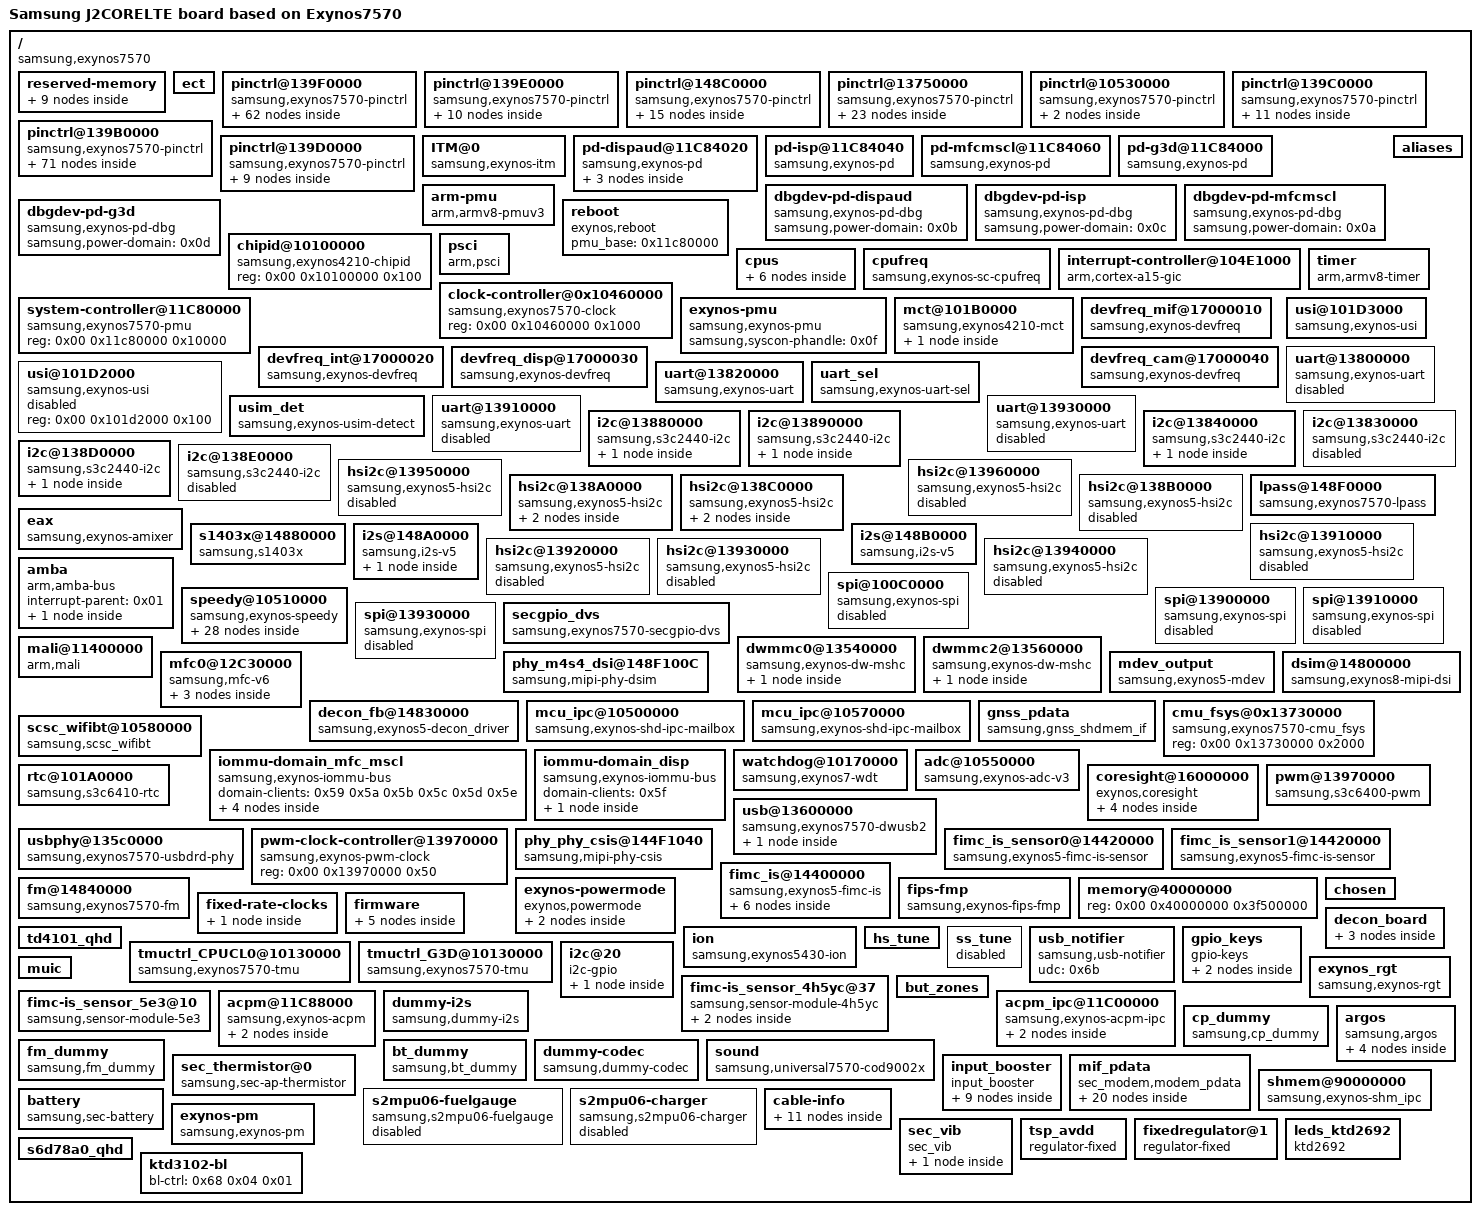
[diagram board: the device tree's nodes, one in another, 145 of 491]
/dts-v1/;

/memreserve/	0x000000007e700000 0x0000000000100000;
/ {
	compatible = "samsung,exynos7570", "samsung,exynos4210";
	interrupt-parent = <0x01>;
	#address-cells = <0x02>;
	#size-cells = <0x01>;
	model = "Samsung J2CORELTE board based on Exynos7570";
	model_info-chip = <0x1d92>;
	model_info-platform = "android";
	model_info-subtype = "samsung";
	model_info-hw_rev = <0x00>;
	model_info-hw_rev_end = <0x00>;

	reserved-memory {
		#address-cells = <0x02>;
		#size-cells = <0x01>;
		ranges;

		camera {
			compatible = "exynos8890-ion,camera";
			reg = <0x00 0x710ef000 0x1000>;
			id = <0x0a>;
		};

		video_nfw {
			compatible = "exynos7570-mfc,vnfw";
			reg = <0x00 0x710f0000 0x110000>;
			fixed_upper_base = <0xffffff80>;
			fixed_lower_base = <0x40000000>;
		};

		video_stream {
			compatible = "exynos8890-ion,vstream";
			secure;
			reg = <0x00 0x72200000 0x100000>;
			id = <0x03>;
			compat-id = <0x19 0x1f>;
		};

		modem_if {
			compatible = "exynos,modem_if";
			reg = <0x00 0x73400000 0x4c00000>;
		};

		wifibt_if {
			compatible = "exynos,wifibt_if";
			reg = <0x00 0x79000000 0x400000>;
		};

		crypto {
			compatible = "exynos8890-ion,crypto";
			reusable;
			reg = <0x00 0x79400000 0x800000>;
			id = <0x01>;
		};

		video_frame {
			compatible = "exynos8890-ion,vframe";
			secure;
			reusable;
			ion,bulk_reclaim;
			reg = <0x00 0x79c00000 0x3800000>;
			id = <0x05>;
			compat-id = <0x1a 0x1d>;
		};

		video_scaler {
			compatible = "exynos8890-ion,vscaler";
			secure;
			reusable;
			reg = <0x00 0x71200000 0x1000000>;
			id = <0x06>;
			compat-id = <0x1c>;
		};

		gnss_if {
			compatible = "exynos,gnss_if";
			reg = <0x00 0x7e100000 0x200000>;
		};
	};

	ect {
		parameter_address = <0x7e0fa000>;
		parameter_size = <0x6000>;
	};

	pinctrl@139F0000 {
		compatible = "samsung,exynos7570-pinctrl";
		reg = <0x00 0x139f0000 0x1000>;
		interrupts = <0x00 0x00 0x00 0x00 0x01 0x00 0x00 0x02 0x00 0x00 0x03 0x00 0x00 0x04 0x00 0x00 0x05 0x00 0x00 0x06 0x00 0x00 0x07 0x00 0x00 0x08 0x00 0x00 0x09 0x00 0x00 0x0a 0x00 0x00 0x0b 0x00 0x00 0x0c 0x00 0x00 0x0d 0x00 0x00 0x0e 0x00 0x00 0x0f 0x00>;
		pinctrl-names = "default";
		pinctrl-0 = <0x02>;

		etc0 {
			gpio-controller;
			#gpio-cells = <0x02>;
			interrupt-controller;
			#interrupt-cells = <0x02>;
		};

		etc1 {
			gpio-controller;
			#gpio-cells = <0x02>;
			interrupt-controller;
			#interrupt-cells = <0x02>;
		};

		gpa0 {
			gpio-controller;
			#gpio-cells = <0x02>;
			interrupt-controller;
			#interrupt-cells = <0x02>;
			interrupt-parent = <0x01>;
			interrupts = <0x00 0x00 0x00 0x00 0x01 0x00 0x00 0x02 0x00 0x00 0x03 0x00 0x00 0x04 0x00 0x00 0x05 0x00 0x00 0x06 0x00 0x00 0x07 0x00>;
			linux,phandle = <0x3a>;
			phandle = <0x3a>;
		};

		dwmmc2_cd_ext_irq {
			samsung,pins = "gpa0-1";
			samsung,pin-function = <0x0f>;
			samsung,pin-pud = <0x00>;
			samsung,pin-drv = <0x04>;
			linux,phandle = <0x4e>;
			phandle = <0x4e>;
		};

		gpa1 {
			gpio-controller;
			#gpio-cells = <0x02>;
			interrupt-controller;
			#interrupt-cells = <0x03>;
			interrupt-parent = <0x01>;
			interrupts = <0x00 0x08 0x00 0x00 0x09 0x00 0x00 0x0a 0x00 0x00 0x0b 0x00 0x00 0x0c 0x00 0x00 0x0d 0x00 0x00 0x0e 0x00 0x00 0x0f 0x00>;
			linux,phandle = <0x19>;
			phandle = <0x19>;
		};

		gpa2 {
			gpio-controller;
			#gpio-cells = <0x02>;
			interrupt-controller;
			#interrupt-cells = <0x02>;
			linux,phandle = <0x22>;
			phandle = <0x22>;
		};

		gpq0 {
			gpio-controller;
			#gpio-cells = <0x02>;
			interrupt-controller;
			#interrupt-cells = <0x02>;
		};

		uart2-bus {
			samsung,pins = "gpa1-6", "gpa1-5";
			samsung,pin-function = <0x03>;
			samsung,pin-pud = <0x00>;
			linux,phandle = <0x13>;
			phandle = <0x13>;
		};

		uart2-sleep {
			samsung,pins = "gpa1-6";
			samsung,pin-function = <0x00>;
			samsung,pin-pud = <0x01>;
			linux,phandle = <0x14>;
			phandle = <0x14>;
		};

		i2c6-bus {
			samsung,pins = "gpa1-6", "gpa1-5";
			samsung,pin-function = <0x02>;
			samsung,pin-pud = <0x03>;
			samsung,pin-drv = <0x00>;
			linux,phandle = <0x23>;
			phandle = <0x23>;
		};

		cp_gpio {
			samsung,pins = "gpa1-7", "gpa2-1";
			samsung,pin-function = <0x04>;
			samsung,pin-pud = <0x00>;
		};

		cp_gpio_on5 {
			samsung,pins = "gpa1-7";
			samsung,pin-function = <0x04>;
			samsung,pin-pud = <0x00>;
		};

		cp_gpio_j3pop_old {
			samsung,pins = "gpa1-3";
			samsung,pin-function = <0x04>;
			samsung,pin-pud = <0x00>;
		};

		cp_gpio_j3pop {
			samsung,pins = "gpa2-3";
			samsung,pin-function = <0x04>;
			samsung,pin-pud = <0x00>;
		};

		cp_gpio_x4 {
			samsung,pins = "gpa1-7", "gpa2-0", "gpa2-1", "gpa2-4";
			samsung,pin-function = <0x04>;
			samsung,pin-pud = <0x00>;
		};

		cp_gpio_w {
			samsung,pins = "gpa2-5", "gpa2-6";
			samsung,pin-function = <0x04>;
			samsung,pin-pud = <0x00>;
		};

		cp_gpio_iot {
			samsung,pins = "gpa1-3", "gpa2-0", "gpa2-2", "gpa2-7";
			samsung,pin-function = <0x04>;
			samsung,pin-pud = <0x00>;
		};

		cp_gpio_j3y17_rev0 {
			samsung,pins = "gpa1-7", "gpa2-6", "gpa2-5";
			samsung,pin-function = <0x04>;
			samsung,pin-pud = <0x00>;
		};

		cp_gpio_j3y17_rev1 {
			samsung,pins = "gpa1-7", "gpa2-6";
			samsung,pin-function = <0x04>;
			samsung,pin-pud = <0x00>;
		};

		cp_gpio_j4lte {
			samsung,pins = "gpa2-6";
			samsung,pin-function = <0x04>;
			samsung,pin-pud = <0x00>;
		};

		cp_gpio_j2corelte {
			samsung,pins = "gpa1-7", "gpa2-6", "gpa2-7";
			samsung,pin-function = <0x04>;
			samsung,pin-pud = <0x00>;
			linux,phandle = <0x7f>;
			phandle = <0x7f>;
		};

		cp_gpio_tabes_vzw {
			samsung,pins = "gpa2-0", "gpa2-1", "gpa2-2";
			samsung,pin-function = <0x04>;
			samsung,pin-pud = <0x00>;
		};

		cp_gpio_tabes_vzw_rev1 {
			samsung,pins = "gpa1-7", "gpa2-0", "gpa2-1", "gpa2-2";
			samsung,pin-function = <0x04>;
			samsung,pin-pud = <0x00>;
		};

		cp_gpio_j3neoelte {
			samsung,pins = "gpa1-7", "gpa2-2", "gpa2-3", "gpa2-4", "gpa2-5", "gpa2-6", "gpa2-7";
			samsung,pin-function = <0x04>;
			samsung,pin-pud = <0x00>;
		};

		sim_gpio_default_on5 {
			samsung,pins = "gpa2-4";
			samsung,pin-function = <0x00>;
			samsung,pin-pud = <0x00>;
		};

		sim0_gpio_on5 {
			samsung,pins = "gpa2-4";
			samsung,pin-function = <0x0f>;
			samsung,pin-pud = <0x00>;
		};

		sim1_gpio_on5 {
			samsung,pins = "gpa1-4";
			samsung,pin-function = <0x0f>;
			samsung,pin-pud = <0x00>;
		};

		fimc-is-flash {
			samsung,pins = "gpa0-0";
			samsung,pin-function = <0x01>;
			samsung,pin-pud = <0x00>;
			samsung,pin-drv = <0x00>;
			linux,phandle = <0x74>;
			phandle = <0x74>;
		};

		uart3-bus-single {
			samsung,pins = "gpa2-0", "gpa1-7", "gpa2-1", "gpa2-2";
			samsung,pin-function = <0x02>;
			samsung,pin-pud = <0x00>;
			linux,phandle = <0x15>;
			phandle = <0x15>;
		};

		uart3-bus-dual {
			samsung,pins = "gpa2-0", "gpa1-7";
			samsung,pin-function = <0x02>;
			samsung,pin-pud = <0x00>;
		};

		uart4-bus-single {
			samsung,pins = "gpa2-5", "gpa2-4", "gpa2-6", "gpa2-7";
			samsung,pin-function = <0x02>;
			samsung,pin-pud = <0x00>;
			linux,phandle = <0x16>;
			phandle = <0x16>;
		};

		uart4-bus-dual {
			samsung,pins = "gpa2-5", "gpa2-4";
			samsung,pin-function = <0x02>;
			samsung,pin-pud = <0x00>;
		};

		hs-i2c5-bus {
			samsung,pins = "gpa2-0", "gpa1-7";
			samsung,pin-function = <0x02>;
			samsung,pin-pud = <0x03>;
			samsung,pin-drv = <0x00>;
			linux,phandle = <0x31>;
			phandle = <0x31>;
		};

		hs-i2c6-bus {
			samsung,pins = "gpa2-2", "gpa2-1";
			samsung,pin-function = <0x02>;
			samsung,pin-pud = <0x03>;
			samsung,pin-drv = <0x00>;
			linux,phandle = <0x32>;
			phandle = <0x32>;
		};

		hs-i2c7-bus {
			samsung,pins = "gpa2-5", "gpa2-4";
			samsung,pin-function = <0x02>;
			samsung,pin-pud = <0x03>;
			samsung,pin-drv = <0x00>;
			linux,phandle = <0x33>;
			phandle = <0x33>;
		};

		hs-i2c8-bus {
			samsung,pins = "gpa2-7", "gpa2-6";
			samsung,pin-function = <0x02>;
			samsung,pin-pud = <0x03>;
			samsung,pin-drv = <0x00>;
			linux,phandle = <0x34>;
			phandle = <0x34>;
		};

		spi2-bus {
			samsung,pins = "gpa2-0", "gpa1-7", "gpa2-2";
			samsung,pin-function = <0x02>;
			samsung,pin-pud = <0x03>;
			samsung,pin-drv = <0x00>;
			linux,phandle = <0x3e>;
			phandle = <0x3e>;
		};

		spi2-cs-0 {
			samsung,pins = "gpa2-1";
			samsung,pin-function = <0x01>;
			samsung,pin-pud = <0x03>;
			samsung,pin-drv = <0x00>;
		};

		spi3-bus {
			samsung,pins = "gpa2-5", "gpa2-4", "gpa2-7";
			samsung,pin-function = <0x02>;
			samsung,pin-pud = <0x03>;
			samsung,pin-drv = <0x00>;
			linux,phandle = <0x3f>;
			phandle = <0x3f>;
		};

		spi3-cs-0 {
			samsung,pins = "gpa2-6";
			samsung,pin-function = <0x01>;
			samsung,pin-pud = <0x03>;
			samsung,pin-drv = <0x00>;
		};

		fimc_is_mclk1_in {
			samsung,pins = "gpa2-3";
			samsung,pin-function = <0x00>;
			samsung,pin-pud = <0x00>;
			samsung,pin-drv = <0x00>;
		};

		fimc_is_mclk1_out {
			samsung,pins = "gpa2-3";
			samsung,pin-function = <0x01>;
			samsung,pin-pud = <0x01>;
			samsung,pin-drv = <0x02>;
		};

		fimc_is_mclk1_fn {
			samsung,pins = "gpa2-3";
			samsung,pin-function = <0x02>;
			samsung,pin-pud = <0x00>;
			samsung,pin-drv = <0x01>;
		};

		wakeup-interrupt-controller {
			compatible = "samsung,exynos4210-wakeup-eint";
			interrupt-parent = <0x01>;
			interrupts = <0x00 0x10 0x00>;
			samsung,eint-flt-conf;
		};

		key-volup {
			samsung,pins = "gpa0-7";
			samsung,pin-function = <0x0f>;
			samsung,pin-pud = <0x03>;
			samsung,pin-drv = <0x00>;
			linux,phandle = <0x6d>;
			phandle = <0x6d>;
		};

		key-voldown {
			samsung,pins = "gpa2-3";
			samsung,pin-function = <0x0f>;
			samsung,pin-pud = <0x03>;
			samsung,pin-drv = <0x00>;
			linux,phandle = <0x6c>;
			phandle = <0x6c>;
		};

		if-irq {
			samsung,pins = "gpa0-5";
			samsung,pin-pud = <0x03>;
			samsung,pin-drv = <0x03>;
			linux,phandle = <0x39>;
			phandle = <0x39>;
		};

		muic-irq {
			samsung,pins = "gpa1-1";
			samsung,pin-pud = <0x00>;
			samsung,pin-drv = <0x00>;
			linux,phandle = <0x18>;
			phandle = <0x18>;
		};

		nfc-clkreq-int {
			samsung,pins = "gpa0-6";
			samsung,pin-function = <0x00>;
			samsung,pin-pud = <0x00>;
		};

		tkey-irq {
			samsung,pins = "gpa0-2";
			samsung,pin-function = <0x0f>;
			samsung,pin-pud = <0x00>;
			samsung,pin-drv = <0x00>;
			linux,phandle = <0x71>;
			phandle = <0x71>;
		};

		tkey-input {
			samsung,pins = "gpa0-2";
			samsung,pin-function = <0x00>;
			samsung,pin-pud = <0x00>;
			samsung,pin-drv = <0x00>;
			linux,phandle = <0x72>;
			phandle = <0x72>;
		};

		acc_int {
			samsung,pins = "gpa2-2";
			samsung,pin-function = <0x00>;
			samsung,pin-pud = <0x00>;
			samsung,pin-drv = <0x00>;
			linux,phandle = <0x21>;
			phandle = <0x21>;
		};

		prox_int {
			samsung,pins = "gpa1-0";
			samsung,pin-function = <0x00>;
			samsung,pin-pud = <0x00>;
			samsung,pin-drv = <0x00>;
		};

		initial-state {
			linux,phandle = <0x02>;
			phandle = <0x02>;

			gpa1-2 {
				samsung,pins = "gpa1-2";
				samsung,pin-function = <0x00>;
				samsung,pin-pud = <0x01>;
				samsung,pin-drv = <0x00>;
			};

			gpa1-4 {
				samsung,pins = "gpa1-4";
				samsung,pin-function = <0x00>;
				samsung,pin-pud = <0x01>;
				samsung,pin-drv = <0x00>;
			};

			gpa2-4 {
				samsung,pins = "gpa2-4";
				samsung,pin-function = <0x00>;
				samsung,pin-pud = <0x01>;
				samsung,pin-drv = <0x00>;
			};

			gpa2-5 {
				samsung,pins = "gpa2-5";
				samsung,pin-function = <0x00>;
				samsung,pin-pud = <0x01>;
				samsung,pin-drv = <0x00>;
			};

			gpa1-3 {
				samsung,pins = "gpa1-3";
				samsung,pin-function = <0x00>;
				samsung,pin-pud = <0x01>;
				samsung,pin-drv = <0x00>;
			};

			gpq0-0 {
				samsung,pins = "gpq0-0";
				samsung,pin-function = <0x00>;
				samsung,pin-pud = <0x01>;
				samsung,pin-drv = <0x00>;
			};
		};

		dwmmc2_tflash_en {
			samsung,pins = "gpa0-3";
			samsung,pin-function = <0x01>;
			samsung,pin-val = <0x01>;
			samsung,pin-pud = <0x00>;
			samsung,pin-drv = <0x04>;
			linux,phandle = <0x4f>;
			phandle = <0x4f>;
		};

		key-home {
			samsung,pins = "gpa0-4";
			samsung,pin-function = <0x0f>;
			samsung,pin-pud = <0x03>;
			samsung,pin-drv = <0x00>;
		};
	};

	pinctrl@139E0000 {
		compatible = "samsung,exynos7570-pinctrl";
		reg = <0x00 0x139e0000 0x1000>;
		interrupts = <0x00 0x1b9 0x00>;
		pinctrl-names = "sleep";
		pinctrl-0 = <0x03>;

		gpc7 {
			gpio-controller;
			#gpio-cells = <0x02>;
			interrupt-controller;
			#interrupt-cells = <0x02>;
			linux,phandle = <0x68>;
			phandle = <0x68>;
		};

		spi0-bus {
			samsung,pins = "gpc7-3", "gpc7-2", "gpc7-0";
			samsung,pin-function = <0x02>;
			samsung,pin-pud = <0x03>;
			samsung,pin-drv = <0x00>;
			linux,phandle = <0x3c>;
			phandle = <0x3c>;
		};

		spi0-cs-0 {
			samsung,pins = "gpc7-1";
			samsung,pin-function = <0x01>;
			samsung,pin-pud = <0x03>;
			samsung,pin-drv = <0x00>;
		};

		spi0-cs-1 {
			samsung,pins = "gpc7-4";
			samsung,pin-function = <0x01>;
			samsung,pin-pud = <0x03>;
			samsung,pin-drv = <0x00>;
		};

		sleep-state {
			linux,phandle = <0x03>;
			phandle = <0x03>;

			gpc7-0 {
				samsung,pins = "gpc7-0";
				samsung,pin-con-pdn = <0x02>;
				samsung,pin-pud-pdn = <0x01>;
			};

			gpc7-1 {
				samsung,pins = "gpc7-1";
				samsung,pin-con-pdn = <0x02>;
				samsung,pin-pud-pdn = <0x01>;
			};

			gpc7-2 {
				samsung,pins = "gpc7-2";
				samsung,pin-con-pdn = <0x02>;
				samsung,pin-pud-pdn = <0x01>;
			};

			gpc7-3 {
				samsung,pins = "gpc7-3";
				samsung,pin-con-pdn = <0x02>;
				samsung,pin-pud-pdn = <0x01>;
			};

			gpc7-4 {
				samsung,pins = "gpc7-4";
				samsung,pin-con-pdn = <0x02>;
				samsung,pin-pud-pdn = <0x01>;
			};
		};
	};

	pinctrl@148C0000 {
		compatible = "samsung,exynos7570-pinctrl";
		reg = <0x00 0x148c0000 0x1000>;
		interrupts = <0x00 0x44 0x00>;
		pinctrl-names = "sleep";
		pinctrl-0 = <0x04>;

		gpz1 {
			gpio-controller;
			#gpio-cells = <0x02>;
			interrupt-controller;
			#interrupt-cells = <0x02>;
		};

		i2s-pmic-bus {
			samsung,pins = "gpz1-0", "gpz1-2", "gpz1-3";
			samsung,pin-function = <0x02>;
			samsung,pin-pud = <0x01>;
			samsung,pin-drv = <0x00>;
			linux,phandle = <0x2d>;
			phandle = <0x2d>;
		};

		i2s-pmic-bus-idle {
			samsung,pins = "gpz1-0", "gpz1-2", "gpz1-3";
			samsung,pin-function = <0x00>;
			samsung,pin-pud = <0x01>;
			samsung,pin-drv = <0x00>;
			linux,phandle = <0x2f>;
			phandle = <0x2f>;
		};

		i2s-codec-clk {
			samsung,pins = "gpz1-4";
			samsung,pin-function = <0x02>;
			samsung,pin-pud = <0x01>;
			samsung,pin-drv = <0x00>;
			linux,phandle = <0x2e>;
			phandle = <0x2e>;
		};

		i2s-amp-bus {
			samsung,pins = "gpz1-5";
			samsung,pin-function = <0x02>;
			samsung,pin-pud = <0x03>;
			samsung,pin-drv = <0x02>;
		};

		i2s-amp-bus-idle {
			samsung,pins = "gpz1-5";
			samsung,pin-function = <0x00>;
			samsung,pin-pud = <0x03>;
			samsung,pin-drv = <0x02>;
		};

		fm-speedy-bus {
			samsung,pins = "gpz1-6";
			samsung,pin-function = <0x02>;
			samsung,pin-pud = <0x03>;
			samsung,pin-drv = <0x02>;
		};

		fm-speedy-bus-idle {
			samsung,pins = "gpz1-6";
			samsung,pin-function = <0x00>;
			samsung,pin-pud = <0x03>;
			samsung,pin-drv = <0x02>;
		};

		sleep-state {
			linux,phandle = <0x04>;
			phandle = <0x04>;

			gpz1-0 {
				samsung,pins = "gpz1-0";
				samsung,pin-con-pdn = <0x02>;
				samsung,pin-pud-pdn = <0x01>;
			};

			gpz1-1 {
				samsung,pins = "gpz1-1";
				samsung,pin-con-pdn = <0x02>;
				samsung,pin-pud-pdn = <0x01>;
			};

			gpz1-2 {
				samsung,pins = "gpz1-2";
				samsung,pin-con-pdn = <0x02>;
				samsung,pin-pud-pdn = <0x01>;
			};

			gpz1-3 {
				samsung,pins = "gpz1-3";
				samsung,pin-con-pdn = <0x02>;
				samsung,pin-pud-pdn = <0x01>;
			};

			gpz1-5 {
				samsung,pins = "gpz1-5";
				samsung,pin-con-pdn = <0x02>;
				samsung,pin-pud-pdn = <0x01>;
			};

			gpz1-6 {
				samsung,pins = "gpz1-6";
				samsung,pin-con-pdn = <0x02>;
				samsung,pin-pud-pdn = <0x01>;
			};
		};
	};

	pinctrl@13750000 {
		compatible = "samsung,exynos7570-pinctrl";
		reg = <0x00 0x13750000 0x1000>;
		interrupts = <0x00 0xfa 0x00>;
		pinctrl-names = "sleep";
		pinctrl-0 = <0x05>;

		gpr0 {
			gpio-controller;
			#gpio-cells = <0x02>;
			interrupt-controller;
			#interrupt-cells = <0x02>;
		};

		gpr1 {
			gpio-controller;
			#gpio-cells = <0x02>;
			interrupt-controller;
			#interrupt-cells = <0x02>;
		};

		gpr4 {
			gpio-controller;
			#gpio-cells = <0x02>;
			interrupt-controller;
			#interrupt-cells = <0x02>;
		};

		sd0-clk {
			samsung,pins = "gpr0-0";
			samsung,pin-function = <0x02>;
			samsung,pin-pud = <0x00>;
			samsung,pin-drv = <0x02>;
			linux,phandle = <0x40>;
			phandle = <0x40>;
		};

		sd0-cmd {
			samsung,pins = "gpr0-1";
			samsung,pin-function = <0x02>;
			samsung,pin-pud = <0x03>;
			samsung,pin-drv = <0x02>;
			linux,phandle = <0x41>;
			phandle = <0x41>;
		};

		sd0-rdqs {
			samsung,pins = "gpr0-2";
			samsung,pin-function = <0x02>;
			samsung,pin-pud = <0x01>;
			samsung,pin-drv = <0x02>;
			linux,phandle = <0x42>;
			phandle = <0x42>;
		};

		sd0-clk_fast_slew_rate_1x {
			samsung,pins = "gpr0-0";
			samsung,pin-function = <0x02>;
			samsung,pin-pud = <0x00>;
			samsung,pin-drv = <0x00>;
			linux,phandle = <0x46>;
			phandle = <0x46>;
		};

		sd0-clk_fast_slew_rate_2x {
			samsung,pins = "gpr0-0";
			samsung,pin-function = <0x02>;
			samsung,pin-pud = <0x00>;
			samsung,pin-drv = <0x01>;
			linux,phandle = <0x47>;
			phandle = <0x47>;
		};

		sd0-clk_fast_slew_rate_3x {
			samsung,pins = "gpr0-0";
			samsung,pin-function = <0x02>;
			samsung,pin-pud = <0x00>;
			samsung,pin-drv = <0x02>;
			linux,phandle = <0x48>;
			phandle = <0x48>;
		};

		sd0-clk_fast_slew_rate_4x {
			samsung,pins = "gpr0-0";
			samsung,pin-function = <0x02>;
			samsung,pin-pud = <0x00>;
			samsung,pin-drv = <0x03>;
			linux,phandle = <0x49>;
			phandle = <0x49>;
		};

		sd0-bus-width1 {
			samsung,pins = "gpr1-0";
			samsung,pin-function = <0x02>;
			samsung,pin-pud = <0x03>;
			samsung,pin-drv = <0x02>;
			linux,phandle = <0x43>;
			phandle = <0x43>;
		};

		sd0-bus-width4 {
			samsung,pins = "gpr1-1", "gpr1-2", "gpr1-3";
			samsung,pin-function = <0x02>;
			samsung,pin-pud = <0x03>;
			samsung,pin-drv = <0x02>;
			linux,phandle = <0x44>;
			phandle = <0x44>;
		};

		sd0-bus-width8 {
			samsung,pins = "gpr1-4", "gpr1-5", "gpr1-6", "gpr1-7";
			samsung,pin-function = <0x02>;
			samsung,pin-pud = <0x03>;
			samsung,pin-drv = <0x02>;
			linux,phandle = <0x45>;
			phandle = <0x45>;
		};

		sd2-clk {
			samsung,pins = "gpr4-0";
			samsung,pin-function = <0x02>;
			samsung,pin-pud = <0x00>;
			samsung,pin-drv = <0x02>;
			linux,phandle = <0x4a>;
			phandle = <0x4a>;
		};

		sd2-cmd {
			samsung,pins = "gpr4-1";
			samsung,pin-function = <0x02>;
			samsung,pin-pud = <0x03>;
			samsung,pin-drv = <0x02>;
			linux,phandle = <0x4b>;
			phandle = <0x4b>;
		};

		sd2-bus-width1 {
			samsung,pins = "gpr4-2";
			samsung,pin-function = <0x02>;
			samsung,pin-pud = <0x03>;
			samsung,pin-drv = <0x02>;
			linux,phandle = <0x4c>;
			phandle = <0x4c>;
		};

		sd2-bus-width4 {
			samsung,pins = "gpr4-3", "gpr4-4", "gpr4-5";
			samsung,pin-function = <0x02>;
			samsung,pin-pud = <0x03>;
			samsung,pin-drv = <0x02>;
			linux,phandle = <0x4d>;
			phandle = <0x4d>;
		};

		sd2-clk_fast_slew_rate_1x {
			samsung,pins = "gpr4-0";
			samsung,pin-function = <0x02>;
			samsung,pin-pud = <0x00>;
			samsung,pin-drv = <0x00>;
			linux,phandle = <0x50>;
			phandle = <0x50>;
		};

		sd2-clk_fast_slew_rate_2x {
			samsung,pins = "gpr4-0";
			samsung,pin-function = <0x02>;
			samsung,pin-pud = <0x00>;
			samsung,pin-drv = <0x01>;
			linux,phandle = <0x51>;
			phandle = <0x51>;
		};

		sd2-clk_fast_slew_rate_3x {
			samsung,pins = "gpr4-0";
			samsung,pin-function = <0x02>;
			samsung,pin-pud = <0x00>;
			samsung,pin-drv = <0x02>;
			linux,phandle = <0x52>;
			phandle = <0x52>;
		};

		sd2-clk_fast_slew_rate_4x {
			samsung,pins = "gpr4-0";
			samsung,pin-function = <0x02>;
			samsung,pin-pud = <0x00>;
			samsung,pin-drv = <0x03>;
			linux,phandle = <0x53>;
			phandle = <0x53>;
		};

		sleep-state {
			linux,phandle = <0x05>;
			phandle = <0x05>;

			gpr0-1 {
				samsung,pins = "gpr0-1";
				samsung,pin-con-pdn = <0x02>;
				samsung,pin-pud-pdn = <0x00>;
			};
		};
	};

	pinctrl@10530000 {
		compatible = "samsung,exynos7570-pinctrl";
		reg = <0x00 0x10530000 0x1000>;
		interrupts = <0x00 0x188 0x00>;

		gpm0 {
			gpio-controller;
			#gpio-cells = <0x02>;
			interrupt-controller;
			#interrupt-cells = <0x02>;
		};

		speedy-bus {
			samsung,pins = "gpm0-0";
			samsung,pin-function = <0x02>;
			samsung,pin-drv = <0x00>;
			samsung,pin-con-pdn = <0x03>;
			linux,phandle = <0x35>;
			phandle = <0x35>;
		};
	};

	pinctrl@139C0000 {
		compatible = "samsung,exynos7570-pinctrl";
		reg = <0x00 0x139c0000 0x1000>;
		interrupts = <0x00 0x1b7 0x00>;
		pinctrl-names = "sleep";
		pinctrl-0 = <0x06>;

		gpc2 {
			gpio-controller;
			#gpio-cells = <0x02>;
			interrupt-controller;
			#interrupt-cells = <0x02>;
			linux,phandle = <0x66>;
			phandle = <0x66>;
		};

		i2c2-bus {
			samsung,pins = "gpc2-1", "gpc2-0";
			samsung,pin-function = <0x02>;
			samsung,pin-pud = <0x00>;
			samsung,pin-drv = <0x00>;
			linux,phandle = <0x1a>;
			phandle = <0x1a>;
		};

		gpio-nfc {
			samsung,pins = "gpc2-2";
			samsung,pin-function = <0x01>;
			samsung,pin-pud = <0x00>;
			samsung,pin-drv = <0x00>;
			samsung,pin-con-pdn = <0x03>;
			samsung,pin-val = <0x01>;
		};

		nfc_pd {
			samsung,pins = "gpc2-2";
			samsung,pin-function = <0x02>;
			samsung,pin-pud = <0x03>;
			samsung,pin-drv = <0x00>;
		};

		nfc_clk_req {
			samsung,pins = "gpc2-3";
			samsung,pin-function = <0x02>;
			samsung,pin-pud = <0x01>;
			samsung,pin-drv = <0x00>;
		};

		fm-lna-en {
			samsung,pins = "gpc2-2";
			samsung,pin-function = <0x01>;
			samsung,pin-pud = <0x00>;
			samsung,pin-val = <0x00>;
			linux,phandle = <0x67>;
			phandle = <0x67>;
		};

		sleep-state {
			linux,phandle = <0x06>;
			phandle = <0x06>;

			gpc2-0 {
				samsung,pins = "gpc2-0";
				samsung,pin-con-pdn = <0x02>;
				samsung,pin-pud-pdn = <0x01>;
			};

			gpc2-1 {
				samsung,pins = "gpc2-1";
				samsung,pin-con-pdn = <0x02>;
				samsung,pin-pud-pdn = <0x01>;
			};

			gpc2-2 {
				samsung,pins = "gpc2-2";
				samsung,pin-con-pdn = <0x03>;
				samsung,pin-pud-pdn = <0x00>;
			};

			gpc2-3 {
				samsung,pins = "gpc2-3";
				samsung,pin-con-pdn = <0x02>;
				samsung,pin-pud-pdn = <0x01>;
			};
		};
	};

	pinctrl@139B0000 {
		compatible = "samsung,exynos7570-pinctrl";
		reg = <0x00 0x139b0000 0x1000>;
		interrupts = <0x00 0x1b6 0x00>;
		pinctrl-names = "default", "sleep";
		pinctrl-0 = <0x07>;
		pinctrl-1 = <0x08>;

		gpc0 {
			gpio-controller;
			#gpio-cells = <0x02>;
			interrupt-controller;
			#interrupt-cells = <0x02>;
		};

		gpc1 {
			gpio-controller;
			#gpio-cells = <0x02>;
			interrupt-controller;
			#interrupt-cells = <0x02>;
		};

		gpc4 {
			gpio-controller;
			#gpio-cells = <0x02>;
			interrupt-controller;
			#interrupt-cells = <0x02>;
			linux,phandle = <0x6e>;
			phandle = <0x6e>;
		};

		gpd1 {
			gpio-controller;
			#gpio-cells = <0x02>;
			interrupt-controller;
			#interrupt-cells = <0x02>;
			linux,phandle = <0x6a>;
			phandle = <0x6a>;
		};

		gpe0 {
			gpio-controller;
			#gpio-cells = <0x02>;
			interrupt-controller;
			#interrupt-cells = <0x02>;
		};

		gpf0 {
			gpio-controller;
			#gpio-cells = <0x02>;
			interrupt-controller;
			#interrupt-cells = <0x02>;
			linux,phandle = <0x28>;
			phandle = <0x28>;
		};

		gpf1 {
			gpio-controller;
			#gpio-cells = <0x02>;
			interrupt-controller;
			#interrupt-cells = <0x02>;
			linux,phandle = <0x2b>;
			phandle = <0x2b>;
		};

		gpf3 {
			gpio-controller;
			#gpio-cells = <0x02>;
			interrupt-controller;
			#interrupt-cells = <0x02>;
			linux,phandle = <0x25>;
			phandle = <0x25>;
		};

		decon_te_on {
			samsung,pins = "gpe0-2";
			samsung,pin-function = <0x02>;
		};

		decon_te_off {
			samsung,pins = "gpe0-2";
			samsung,pin-function = <0x00>;
		};

		uart1-bus {
			samsung,pins = "gpc4-3", "gpc4-2";
			samsung,pin-function = <0x04>;
			samsung,pin-pud = <0x00>;
			linux,phandle = <0x12>;
			phandle = <0x12>;
		};

		i2c1-bus {
			samsung,pins = "gpc1-3", "gpc1-2";
			samsung,pin-function = <0x02>;
			samsung,pin-pud = <0x03>;
			samsung,pin-drv = <0x00>;
			linux,phandle = <0x17>;
			phandle = <0x17>;
		};

		i2c4-bus {
			samsung,pins = "gpc4-1", "gpc4-0";
			samsung,pin-function = <0x02>;
			samsung,pin-pud = <0x03>;
			samsung,pin-drv = <0x00>;
			linux,phandle = <0x1f>;
			phandle = <0x1f>;
		};

		i2c5-bus {
			samsung,pins = "gpc4-3", "gpc4-2";
			samsung,pin-function = <0x02>;
			samsung,pin-pud = <0x03>;
			samsung,pin-drv = <0x00>;
		};

		hs-i2c0-bus {
			samsung,pins = "gpf3-0", "gpf3-1";
			samsung,pin-function = <0x03>;
			samsung,pin-pud = <0x03>;
			samsung,pin-drv = <0x00>;
			samsung,pin-con-pdn = <0x03>;
			linux,phandle = <0x24>;
			phandle = <0x24>;
		};

		hs-i2c1-bus {
			samsung,pins = "gpf3-2", "gpf3-3";
			samsung,pin-function = <0x03>;
			samsung,pin-pud = <0x03>;
			samsung,pin-drv = <0x00>;
			samsung,pin-con-pdn = <0x03>;
			linux,phandle = <0x26>;
			phandle = <0x26>;
		};

		hs-i2c2-bus {
			samsung,pins = "gpf0-1", "gpf0-0";
			samsung,pin-function = <0x02>;
			samsung,pin-pud = <0x00>;
			samsung,pin-drv = <0x00>;
			samsung,pin-con-pdn = <0x03>;
			linux,phandle = <0x27>;
			phandle = <0x27>;
		};

		hs-i2c3-bus {
			samsung,pins = "gpf0-3", "gpf0-2";
			samsung,pin-function = <0x02>;
			samsung,pin-pud = <0x00>;
			samsung,pin-drv = <0x00>;
			samsung,pin-con-pdn = <0x03>;
			linux,phandle = <0x29>;
			phandle = <0x29>;
		};

		hs-i2c4-bus {
			samsung,pins = "gpf1-1", "gpf1-0";
			samsung,pin-function = <0x02>;
			samsung,pin-pud = <0x00>;
			samsung,pin-drv = <0x00>;
			samsung,pin-con-pdn = <0x00>;
			linux,phandle = <0x2a>;
			phandle = <0x2a>;
		};

		spi1-bus {
			samsung,pins = "gpf3-3", "gpf3-2", "gpf3-0";
			samsung,pin-function = <0x02>;
			samsung,pin-pud = <0x03>;
			samsung,pin-drv = <0x00>;
			linux,phandle = <0x3d>;
			phandle = <0x3d>;
		};

		spi1-cs-0 {
			samsung,pins = "gpf3-1";
			samsung,pin-function = <0x01>;
			samsung,pin-pud = <0x03>;
			samsung,pin-drv = <0x00>;
		};

		spi1-cs-1 {
			samsung,pins = "gpd1-0";
			samsung,pin-function = <0x01>;
			samsung,pin-pud = <0x03>;
			samsung,pin-drv = <0x00>;
		};

		pwm-tout0 {
			samsung,pins = "gpc0-1";
			samsung,pin-function = <0x02>;
			samsung,pin-pud = <0x01>;
			samsung,pin-drv = <0x00>;
		};

		pwm-tout1 {
			samsung,pins = "gpc0-2";
			samsung,pin-function = <0x02>;
			samsung,pin-pud = <0x01>;
			samsung,pin-drv = <0x00>;
		};

		fimc_is_mclk0_in {
			samsung,pins = "gpe0-0";
			samsung,pin-function = <0x00>;
			samsung,pin-pud = <0x00>;
			samsung,pin-drv = <0x00>;
			linux,phandle = <0x73>;
			phandle = <0x73>;
		};

		fimc_is_mclk0_out {
			samsung,pins = "gpe0-0";
			samsung,pin-function = <0x01>;
			samsung,pin-pud = <0x01>;
			samsung,pin-drv = <0x02>;
		};

		fimc_is_mclk0_fn {
			samsung,pins = "gpe0-0";
			samsung,pin-function = <0x02>;
			samsung,pin-pud = <0x00>;
			samsung,pin-drv = <0x01>;
			linux,phandle = <0x75>;
			phandle = <0x75>;
		};

		nfc_firm {
			samsung,pins = "gpf3-2";
			samsung,pin-function = <0x01>;
			samsung,pin-pud = <0x00>;
			samsung,pin-val = <0x00>;
		};

		nfc_pvdd_en {
			samsung,pins = "gpc0-1";
			samsung,pin-function = <0x01>;
			samsung,pin-pud = <0x00>;
			samsung,pin-val = <0x00>;
		};

		ese_pvdd_en {
			samsung,pins = "gpf1-1";
			samsung,pin-function = <0x01>;
			samsung,pin-pud = <0x01>;
			samsung,pin-val = <0x00>;
		};

		cfg-i2c {
			samsung,pins = "gpc4-1", "gpc4-0";
			samsung,pin-function = <0x02>;
			samsung,pin-pud = <0x01>;
			samsung,pin-drv = <0x00>;
			linux,phandle = <0x6f>;
			phandle = <0x6f>;
		};

		cfg-gpio {
			samsung,pins = "gpc4-1", "gpc4-0";
			samsung,pin-function = <0x00>;
			samsung,pin-pud = <0x01>;
			samsung,pin-drv = <0x00>;
			linux,phandle = <0x70>;
			phandle = <0x70>;
		};

		sensor_i2c {
			samsung,pins = "gpc4-3", "gpc4-2";
			samsung,pin-function = <0x02>;
			samsung,pin-pud = <0x03>;
			samsung,pin-drv = <0x02>;
			linux,phandle = <0x20>;
			phandle = <0x20>;
		};

		nfc-pwr-en {
			samsung,pins = "gpf1-0";
			samsung,pin-function = <0x01>;
			samsung,pin-pud = <0x00>;
		};

		initial-state {
			linux,phandle = <0x07>;
			phandle = <0x07>;

			gpc0-2 {
				samsung,pins = "gpc0-2";
				samsung,pin-function = <0x00>;
				samsung,pin-pud = <0x01>;
				samsung,pin-drv = <0x00>;
			};

			gpd1-2 {
				samsung,pins = "gpd1-2";
				samsung,pin-function = <0x00>;
				samsung,pin-pud = <0x00>;
				samsung,pin-drv = <0x00>;
			};

			gpd1-3 {
				samsung,pins = "gpd1-3";
				samsung,pin-function = <0x00>;
				samsung,pin-pud = <0x00>;
				samsung,pin-drv = <0x00>;
			};

			gpd1-4 {
				samsung,pins = "gpd1-4";
				samsung,pin-function = <0x00>;
				samsung,pin-pud = <0x00>;
				samsung,pin-drv = <0x00>;
			};

			gpd1-5 {
				samsung,pins = "gpd1-5";
				samsung,pin-function = <0x00>;
				samsung,pin-pud = <0x01>;
				samsung,pin-drv = <0x00>;
			};
		};

		sleep-state {
			linux,phandle = <0x08>;
			phandle = <0x08>;

			gpc0-1 {
				samsung,pins = "gpc0-1";
				samsung,pin-con-pdn = <0x02>;
				samsung,pin-pud-pdn = <0x01>;
			};

			gpc0-2 {
				samsung,pins = "gpc0-2";
				samsung,pin-con-pdn = <0x02>;
				samsung,pin-pud-pdn = <0x01>;
			};

			gpc1-2 {
				samsung,pins = "gpc1-2";
				samsung,pin-con-pdn = <0x03>;
				samsung,pin-pud-pdn = <0x03>;
			};

			gpc1-3 {
				samsung,pins = "gpc1-3";
				samsung,pin-con-pdn = <0x03>;
				samsung,pin-pud-pdn = <0x03>;
			};

			gpc4-0 {
				samsung,pins = "gpc4-0";
				samsung,pin-con-pdn = <0x02>;
				samsung,pin-pud-pdn = <0x00>;
			};

			gpc4-1 {
				samsung,pins = "gpc4-1";
				samsung,pin-con-pdn = <0x02>;
				samsung,pin-pud-pdn = <0x00>;
			};

			gpc4-2 {
				samsung,pins = "gpc4-2";
				samsung,pin-con-pdn = <0x02>;
				samsung,pin-pud-pdn = <0x03>;
			};

			gpc4-3 {
				samsung,pins = "gpc4-3";
				samsung,pin-con-pdn = <0x02>;
				samsung,pin-pud-pdn = <0x03>;
			};

			gpd1-0 {
				samsung,pins = "gpd1-0";
				samsung,pin-con-pdn = <0x03>;
				samsung,pin-pud-pdn = <0x00>;
			};

			gpd1-1 {
				samsung,pins = "gpd1-1";
				samsung,pin-con-pdn = <0x02>;
				samsung,pin-pud-pdn = <0x01>;
			};

			gpd1-2 {
				samsung,pins = "gpd1-2";
				samsung,pin-con-pdn = <0x02>;
				samsung,pin-pud-pdn = <0x00>;
			};

			gpd1-3 {
				samsung,pins = "gpd1-3";
				samsung,pin-con-pdn = <0x02>;
				samsung,pin-pud-pdn = <0x00>;
			};

			gpd1-4 {
				samsung,pins = "gpd1-4";
				samsung,pin-con-pdn = <0x02>;
				samsung,pin-pud-pdn = <0x00>;
			};

			gpd1-5 {
				samsung,pins = "gpd1-5";
				samsung,pin-con-pdn = <0x02>;
				samsung,pin-pud-pdn = <0x01>;
			};

			gpd1-6 {
				samsung,pins = "gpd1-6";
				samsung,pin-con-pdn = <0x02>;
				samsung,pin-pud-pdn = <0x01>;
			};

			gpe0-0 {
				samsung,pins = "gpe0-0";
				samsung,pin-con-pdn = <0x02>;
				samsung,pin-pud-pdn = <0x01>;
			};

			gpe0-1 {
				samsung,pins = "gpe0-1";
				samsung,pin-con-pdn = <0x02>;
				samsung,pin-pud-pdn = <0x01>;
			};

			gpe0-2 {
				samsung,pins = "gpe0-2";
				samsung,pin-con-pdn = <0x02>;
				samsung,pin-pud-pdn = <0x01>;
			};

			gpf0-0 {
				samsung,pins = "gpf0-0";
				samsung,pin-con-pdn = <0x02>;
				samsung,pin-pud-pdn = <0x01>;
			};

			gpf0-1 {
				samsung,pins = "gpf0-1";
				samsung,pin-con-pdn = <0x02>;
				samsung,pin-pud-pdn = <0x01>;
			};

			gpf0-2 {
				samsung,pins = "gpf0-2";
				samsung,pin-con-pdn = <0x02>;
				samsung,pin-pud-pdn = <0x01>;
			};

			gpf0-3 {
				samsung,pins = "gpf0-3";
				samsung,pin-con-pdn = <0x02>;
				samsung,pin-pud-pdn = <0x01>;
			};

			gpf1-0 {
				samsung,pins = "gpf1-0";
				samsung,pin-con-pdn = <0x02>;
				samsung,pin-pud-pdn = <0x01>;
			};

			gpf1-1 {
				samsung,pins = "gpf1-1";
				samsung,pin-con-pdn = <0x02>;
				samsung,pin-pud-pdn = <0x01>;
			};

			gpf3-0 {
				samsung,pins = "gpf3-0";
				samsung,pin-con-pdn = <0x02>;
				samsung,pin-pud-pdn = <0x01>;
			};

			gpf3-1 {
				samsung,pins = "gpf3-1";
				samsung,pin-con-pdn = <0x02>;
				samsung,pin-pud-pdn = <0x01>;
			};

			gpf3-2 {
				samsung,pins = "gpf3-2";
				samsung,pin-con-pdn = <0x02>;
				samsung,pin-pud-pdn = <0x01>;
			};

			gpf3-3 {
				samsung,pins = "gpf3-3";
				samsung,pin-con-pdn = <0x02>;
				samsung,pin-pud-pdn = <0x01>;
			};
		};

		fimc-is-flash-host {
			samsung,pins = "gpf3-3";
			samsung,pin-function = <0x01>;
			samsung,pin-pud = <0x01>;
			samsung,pin-drv = <0x00>;
			linux,phandle = <0x81>;
			phandle = <0x81>;
		};

		fimc-is-flash-is {
			samsung,pins = "gpf3-3";
			samsung,pin-function = <0x01>;
			samsung,pin-pud = <0x01>;
			samsung,pin-drv = <0x00>;
			linux,phandle = <0x80>;
			phandle = <0x80>;
		};
	};

	pinctrl@139D0000 {
		compatible = "samsung,exynos7570-pinctrl";
		reg = <0x00 0x139d0000 0x1000>;
		interrupts = <0x00 0x1b8 0x00>;
		pinctrl-names = "sleep";
		pinctrl-0 = <0x09>;

		gpc3 {
			gpio-controller;
			#gpio-cells = <0x02>;
			interrupt-controller;
			#interrupt-cells = <0x02>;
			linux,phandle = <0x1e>;
			phandle = <0x1e>;
		};

		gpd2 {
			gpio-controller;
			#gpio-cells = <0x02>;
			interrupt-controller;
			#interrupt-cells = <0x02>;
			linux,phandle = <0x69>;
			phandle = <0x69>;
		};

		i2c3-bus {
			samsung,pins = "gpc3-1", "gpc3-0";
			samsung,pin-function = <0x02>;
			samsung,pin-pud = <0x00>;
			samsung,pin-drv = <0x00>;
			linux,phandle = <0x1b>;
			phandle = <0x1b>;
		};

		attn-input {
			samsung,pins = "gpc3-2";
			samsung,pin-function = <0x00>;
			samsung,pin-pud = <0x00>;
			samsung,pin-drv = <0x00>;
			linux,phandle = <0x1d>;
			phandle = <0x1d>;
		};

		attn-irq {
			samsung,pins = "gpc3-2";
			samsung,pin-function = <0x0f>;
			samsung,pin-pud = <0x00>;
			samsung,pin-drv = <0x00>;
			linux,phandle = <0x1c>;
			phandle = <0x1c>;
		};

		sleep-state {
			linux,phandle = <0x09>;
			phandle = <0x09>;

			gpc3-0 {
				samsung,pins = "gpc3-0";
				samsung,pin-con-pdn = <0x02>;
				samsung,pin-pud-pdn = <0x00>;
			};

			gpc3-1 {
				samsung,pins = "gpc3-1";
				samsung,pin-con-pdn = <0x02>;
				samsung,pin-pud-pdn = <0x00>;
			};

			gpc3-2 {
				samsung,pins = "gpc3-2";
				samsung,pin-con-pdn = <0x02>;
				samsung,pin-pud-pdn = <0x00>;
			};
		};
	};

	ITM@0 {
		compatible = "samsung,exynos-itm";
	};

	pd-dispaud@11C84020 {
		compatible = "samsung,exynos-pd";
		reg = <0x00 0x11c84020 0x20>;
		cal_id = <0xb138000d>;
		status = "okay";
		check-cp-status = "true";
		linux,phandle = <0x0b>;
		phandle = <0x0b>;

		spd-aud@11C84020 {
			compatible = "samsung,exynos-spd";
			linux,phandle = <0x2c>;
			phandle = <0x2c>;
		};

		spd-disp@11C84020 {
			compatible = "samsung,exynos-spd";
			linux,phandle = <0x54>;
			phandle = <0x54>;
		};

		spd-fm@11C84020 {
			compatible = "samsung,exynos-spd";
			linux,phandle = <0x65>;
			phandle = <0x65>;
		};
	};

	pd-isp@11C84040 {
		compatible = "samsung,exynos-pd";
		reg = <0x00 0x11c84040 0x20>;
		parent = <0x0a>;
		cal_id = <0xb1380003>;
		devfreq-sync-voltage = <0x03>;
		status = "okay";
		linux,phandle = <0x0c>;
		phandle = <0x0c>;
	};

	pd-mfcmscl@11C84060 {
		compatible = "samsung,exynos-pd";
		reg = <0x00 0x11c84060 0x20>;
		cal_id = <0xb1380008>;
		status = "okay";
		linux,phandle = <0x0a>;
		phandle = <0x0a>;
	};

	pd-g3d@11C84000 {
		compatible = "samsung,exynos-pd";
		reg = <0x00 0x11c84000 0x20>;
		cal_id = <0xb1380000>;
		status = "okay";
		linux,phandle = <0x0d>;
		phandle = <0x0d>;
	};

	dbgdev-pd-dispaud {
		compatible = "samsung,exynos-pd-dbg";
		samsung,power-domain = <0x0b>;
	};

	dbgdev-pd-isp {
		compatible = "samsung,exynos-pd-dbg";
		samsung,power-domain = <0x0c>;
	};

	dbgdev-pd-mfcmscl {
		compatible = "samsung,exynos-pd-dbg";
		samsung,power-domain = <0x0a>;
	};

	dbgdev-pd-g3d {
		compatible = "samsung,exynos-pd-dbg";
		samsung,power-domain = <0x0d>;
	};

	arm-pmu {
		compatible = "arm,armv8-pmuv3";
		interrupts = <0x00 0x32 0x04 0x00 0x33 0x04 0x00 0x34 0x04 0x00 0x35 0x04>;
	};

	aliases {
		pinctrl0 = "/pinctrl@139F0000";
		pinctrl1 = "/pinctrl@148C0000";
		pinctrl2 = "/pinctrl@139E0000";
		pinctrl3 = "/pinctrl@13750000";
		pinctrl4 = "/pinctrl@10530000";
		pinctrl5 = "/pinctrl@139C0000";
		pinctrl6 = "/pinctrl@139B0000";
		pinctrl7 = "/pinctrl@139D0000";
		uart1 = "/uart@13800000";
		uart2 = "/uart@13820000";
		uart3 = "/uart@13910000";
		uart4 = "/uart@13930000";
		hsi2c0 = "/hsi2c@13950000";
		hsi2c1 = "/hsi2c@13960000";
		hsi2c2 = "/hsi2c@138A0000";
		hsi2c3 = "/hsi2c@138C0000";
		hsi2c4 = "/hsi2c@138B0000";
		hsi2c5 = "/hsi2c@13910000";
		hsi2c6 = "/hsi2c@13920000";
		hsi2c7 = "/hsi2c@13930000";
		hsi2c8 = "/hsi2c@13940000";
		spi0 = "/spi@100C0000";
		spi1 = "/spi@13900000";
		spi2 = "/spi@13910000";
		spi3 = "/spi@13930000";
		mshc0 = "/dwmmc0@13540000";
		mshc2 = "/dwmmc2@13560000";
		decon0 = "/decon_fb@14830000";
		dsim0 = "/dsim@14800000";
		tmuctrl0 = "/tmuctrl_CPUCL0@10130000";
		tmuctrl1 = "/tmuctrl_G3D@10130000";
		scaler0 = "/iommu-domain_mfc_mscl/scaler@12C10000";
		mfc0 = "/mfc0@12C30000";
	};

	chipid@10100000 {
		compatible = "samsung,exynos4210-chipid";
		reg = <0x00 0x10100000 0x100>;
	};

	reboot {
		compatible = "exynos,reboot";
		pmu_base = <0x11c80000>;
	};

	cpus {
		#address-cells = <0x02>;
		#size-cells = <0x00>;

		cpu@0 {
			device_type = "cpu";
			compatible = "arm,cortex-a53", "arm,armv8";
			reg = <0x00 0x00>;
			enable-method = "psci";
			cpu-idle-states = <0x0e>;
		};

		cpu@1 {
			device_type = "cpu";
			compatible = "arm,cortex-a53", "arm,armv8";
			reg = <0x00 0x01>;
			enable-method = "psci";
			cpu-idle-states = <0x0e>;
		};

		cpu@2 {
			device_type = "cpu";
			compatible = "arm,cortex-a53", "arm,armv8";
			reg = <0x00 0x02>;
			enable-method = "psci";
			cpu-idle-states = <0x0e>;
		};

		cpu@3 {
			device_type = "cpu";
			compatible = "arm,cortex-a53", "arm,armv8";
			reg = <0x00 0x03>;
			enable-method = "psci";
			cpu-idle-states = <0x0e>;
		};

		idle-states {
			entry-method = "arm,psci";

			cpu-sleep {
				desc = "cpu sleep";
				compatible = "exynos,idle-state";
				arm,psci-suspend-param = <0x10000>;
				entry-latency-us = <0x23>;
				exit-latency-us = <0x5a>;
				min-residency-us = <0x2ee>;
				status = "okay";
				linux,phandle = <0x0e>;
				phandle = <0x0e>;
			};
		};
	};

	psci {
		compatible = "arm,psci";
		method = "smc";
		cpu_suspend = <0xc4000001>;
		cpu_off = <0x84000002>;
		cpu_on = <0xc4000003>;
	};

	cpufreq {
		compatible = "samsung,exynos-sc-cpufreq";
		cl0_idx_num = <0x11>;
		cl0_max_support_idx = <0x03>;
		cl0_min_support_idx = <0x10>;
		cl0_boot_max_qos = <0x1506d0>;
		cl0_boot_min_qos = <0x1506d0>;
		cl0_boot_lock_time = <0x2625a00>;
		cl0_en_ema = <0x00>;
		cl0_regulator = "BUCK1";
		cl0_dvfs_domain_name = "dvfs_cpucl0";
	};

	interrupt-controller@104E1000 {
		compatible = "arm,cortex-a15-gic", "arm,cortex-a9-gic";
		#interrupt-cells = <0x03>;
		#address-cells = <0x00>;
		interrupt-controller;
		reg = <0x00 0x104e1000 0x1000 0x00 0x104e2000 0x1000 0x00 0x104e4000 0x2000 0x00 0x104e6000 0x2000>;
		interrupts = <0x01 0x09 0xf04>;
		linux,phandle = <0x01>;
		phandle = <0x01>;
	};

	timer {
		compatible = "arm,armv8-timer";
		interrupts = <0x01 0x0d 0xff01 0x01 0x0e 0xff01 0x01 0x0b 0xff01 0x01 0x0a 0xff01>;
		clock-frequency = <0x18cba80>;
		use-clocksource-only;
	};

	clock-controller@0x10460000 {
		compatible = "samsung,exynos7570-clock";
		reg = <0x00 0x10460000 0x1000>;
		#clock-cells = <0x01>;
		linux,phandle = <0x11>;
		phandle = <0x11>;
	};

	system-controller@11C80000 {
		compatible = "samsung,exynos7570-pmu", "syscon";
		reg = <0x00 0x11c80000 0x10000>;
		linux,phandle = <0x0f>;
		phandle = <0x0f>;
	};

	exynos-pmu {
		compatible = "samsung,exynos-pmu";
		samsung,syscon-phandle = <0x0f>;
	};

	mct@101B0000 {
		compatible = "samsung,exynos4210-mct";
		reg = <0x00 0x101b0000 0x800>;
		interrupt-controller;
		#interrupt-cells = <0x01>;
		interrupt-parent = <0x10>;
		interrupts = <0x00 0x01 0x02 0x03 0x04 0x05 0x06 0x07 0x08 0x09 0x0a 0x0b>;
		clocks = <0x11 0x01 0x11 0x172>;
		clock-names = "fin_pll", "mct";
		use-clockevent-only;

		mct-map {
			#interrupt-cells = <0x01>;
			#address-cells = <0x00>;
			#size-cells = <0x00>;
			interrupt-map = <0x00 0x01 0x00 0x66 0x00 0x01 0x01 0x00 0x67 0x00 0x02 0x01 0x00 0x68 0x00 0x03 0x01 0x00 0x69 0x00 0x04 0x01 0x00 0x6a 0x00 0x05 0x01 0x00 0x6b 0x00 0x06 0x01 0x00 0x6c 0x00 0x07 0x01 0x00 0x6d 0x00 0x08 0x01 0x00 0x6e 0x00 0x09 0x01 0x00 0x6f 0x00 0x0a 0x01 0x00 0x70 0x00 0x0b 0x01 0x00 0x71 0x00>;
			linux,phandle = <0x10>;
			phandle = <0x10>;
		};
	};

	devfreq_mif@17000010 {
		compatible = "samsung,exynos-devfreq";
		reg = <0x00 0x17000010 0x00>;
		clocks = <0x11 0x3e8 0x11 0x3e9>;
		clock-names = "dvfs_mif", "dvfs_mif_sw";
		devfreq_type = "mif";
		devfreq_domain_name = "dvfs_mif";
		use_delay_time = "true";
		delay_time_list = "20";
		freq_info = <0xa2990 0x65518 0x65518 0x65518 0xa2990 0x65518>;
		boot_qos_timeout = <0x28>;
		use_get_dev = "false";
		polling_ms = <0x00>;
		gov_name = "interactive";
		use_reg = "true";
		use_pd_off = "false";
		reg_name = "BUCK1";
		volt_info = <0x61a8 0x1312d0 0x00 0x13d620>;
		use_tmu = "true";
		use_cl_dvfs = "false";
		use_sw_clk = "true";
	};

	devfreq_int@17000020 {
		compatible = "samsung,exynos-devfreq";
		reg = <0x00 0x17000020 0x00>;
		clocks = <0x11 0x3ea>;
		clock-names = "dvfs_int";
		devfreq_type = "int";
		devfreq_domain_name = "dvfs_int";
		use_delay_time = "false";
		freq_info = <0x72038 0x65518 0x72038 0x65518 0x72038 0x65518>;
		boot_qos_timeout = <0x28>;
		use_get_dev = "false";
		polling_ms = <0x00>;
		gov_name = "interactive";
		use_reg = "true";
		use_pd_off = "false";
		reg_name = "BUCK1";
		volt_info = <0x61a8 0x1312d0 0x00 0x13d620>;
		use_tmu = "true";
		use_cl_dvfs = "false";
		use_sw_clk = "false";
	};

	devfreq_disp@17000030 {
		compatible = "samsung,exynos-devfreq";
		reg = <0x00 0x17000030 0x00>;
		clocks = <0x11 0x3ec>;
		clock-names = "dvfs_disp";
		devfreq_type = "disp";
		devfreq_domain_name = "dvfs_disp";
		use_delay_time = "false";
		freq_info = <0x32c80 0x32c80 0x32c80 0x32c80 0x32c80 0x32c80>;
		boot_qos_timeout = <0x28>;
		use_get_dev = "false";
		polling_ms = <0x00>;
		gov_name = "interactive";
		use_reg = "true";
		use_pd_off = "false";
		reg_name = "BUCK1";
		volt_info = <0x61a8 0x1312d0 0x00 0x13d620>;
		use_tmu = "true";
		use_cl_dvfs = "false";
		use_sw_clk = "false";
	};

	devfreq_cam@17000040 {
		compatible = "samsung,exynos-devfreq";
		reg = <0x00 0x17000040 0x00>;
		clocks = <0x11 0x3eb>;
		clock-names = "dvfs_cam";
		devfreq_type = "cam";
		devfreq_domain_name = "dvfs_cam";
		use_delay_time = "false";
		freq_info = <0x6c660 0x6c660 0x6c660 0x6c660 0x87410 0x6c660>;
		boot_qos_timeout = <0x00>;
		use_get_dev = "false";
		polling_ms = <0x00>;
		gov_name = "interactive";
		use_reg = "true";
		use_pd_off = "true";
		reg_name = "BUCK1";
		volt_info = <0x61a8 0x1312d0 0x00 0x13d620>;
		use_tmu = "true";
		use_cl_dvfs = "false";
		use_sw_clk = "false";
	};

	usi@101D2000 {
		compatible = "samsung,exynos-usi";
		reg = <0x00 0x101d2000 0x100>;
		status = "disabled";
	};

	usi@101D3000 {
		compatible = "samsung,exynos-usi";
		reg = <0x00 0x101d3000 0x100>;
		status = "okay";
		usi_mode = "hsi2c1";
	};

	uart@13800000 {
		compatible = "samsung,exynos-uart";
		samsung,separate-uart-clk;
		reg = <0x00 0x13800000 0x100>;
		samsung,fifo-size = <0x10>;
		interrupts = <0x00 0x1a5 0x00>;
		pinctrl-names = "default";
		pinctrl-0 = <0x12>;
		clocks = <0x11 0x169 0x11 0x15 0x11 0x15>;
		clock-names = "gate_pclk1", "gate_uart1", "sclk_uart1";
		status = "disabled";
	};

	uart@13820000 {
		compatible = "samsung,exynos-uart";
		samsung,separate-uart-clk;
		samsung,alive-io;
		reg = <0x00 0x13820000 0x100>;
		samsung,fifo-size = <0x100>;
		interrupts = <0x00 0x1a7 0x00>;
		pinctrl-names = "default", "uart_sleep";
		pinctrl-0 = <0x13>;
		pinctrl-1 = <0x14>;
		clocks = <0x11 0x168 0x11 0x14 0x11 0x14>;
		clock-names = "gate_pclk2", "gate_uart2", "sclk_uart2";
		status = "okay";
		samsung,uart-logging;
	};

	uart_sel {
		compatible = "samsung,exynos-uart-sel";
		int_ap2cp_uart_noti = <0x0f>;
		mbx_ap2cp_united_status = <0x02>;
		sbi_uart_noti_mask = <0x01>;
		sbi_uart_noti_pos = <0x10>;
	};

	usim_det {
		compatible = "samsung,exynos-usim-detect";
		mbx_ap2cp_united_status = <0x02>;
		mif,int_usim0_det_level = <0x04>;
		mif,int_usim1_det_level = <0x05>;
		sbi_usim0_det_mask = <0x01>;
		sbi_usim0_det_pos = <0x11>;
		sbi_usim1_det_mask = <0x01>;
		sbi_usim1_det_pos = <0x12>;
	};

	uart@13910000 {
		compatible = "samsung,exynos-uart";
		samsung,separate-uart-clk;
		reg = <0x00 0x13910000 0x100>;
		samsung,fifo-size = <0x20>;
		interrupts = <0x00 0x1cd 0x00>;
		pinctrl-names = "default";
		pinctrl-0 = <0x15>;
		clocks = <0x11 0x15f 0x11 0x28 0x11 0x28>;
		clock-names = "gate_pclk3", "gate_uart3", "sclk_uart3";
		status = "disabled";
	};

	uart@13930000 {
		compatible = "samsung,exynos-uart";
		samsung,separate-uart-clk;
		reg = <0x00 0x13930000 0x100>;
		samsung,fifo-size = <0x20>;
		interrupts = <0x00 0x1d1 0x00>;
		pinctrl-names = "default";
		pinctrl-0 = <0x16>;
		clocks = <0x11 0x160 0x11 0x29 0x11 0x29>;
		clock-names = "gate_pclk4", "gate_uart4", "sclk_uart4";
		status = "disabled";
	};

	i2c@13880000 {
		compatible = "samsung,s3c2440-i2c";
		reg = <0x00 0x13880000 0x100>;
		interrupts = <0x00 0x1ad 0x00>;
		#address-cells = <0x01>;
		#size-cells = <0x00>;
		samsung,i2c-clk-logging;
		pinctrl-names = "default";
		pinctrl-0 = <0x17>;
		clocks = <0x11 0x138 0x11 0x138>;
		clock-names = "rate_i2c", "gate_i2c";
		status = "okay";

		muic-universal@14 {
			status = "okay";
			compatible = "muic-universal";
			reg = <0x14>;
			pinctrl-names = "default";
			pinctrl-0 = <0x18>;
			muic-universal,chip_name = "sm,sm5504";
			muic-universal,irq-gpio = <0x19 0x01 0x00>;
		};
	};

	i2c@13890000 {
		compatible = "samsung,s3c2440-i2c";
		reg = <0x00 0x13890000 0x100>;
		interrupts = <0x00 0x1ae 0x00>;
		#address-cells = <0x01>;
		#size-cells = <0x00>;
		pinctrl-names = "default";
		pinctrl-0 = <0x1a>;
		clocks = <0x11 0x137 0x11 0x137>;
		clock-names = "rate_i2c", "gate_i2c";
		status = "okay";
		samsung,i2c-max-bus-freq = <0x61a80>;

		lm3632@11 {
			compatible = "i2c,lm3632";
			reg = <0x11>;
		};
	};

	i2c@13840000 {
		compatible = "samsung,s3c2440-i2c";
		reg = <0x00 0x13840000 0x100>;
		interrupts = <0x00 0x1a9 0x00>;
		#address-cells = <0x01>;
		#size-cells = <0x00>;
		pinctrl-names = "default";
		pinctrl-0 = <0x1b>;
		clocks = <0x11 0x12e 0x11 0x12e>;
		clock-names = "rate_i2c", "gate_i2c";
		status = "okay";
		samsung,i2c-sda-delay = <0x64>;
		samsung,i2c-max-bus-freq = <0x61a80>;

		touchscreen@20 {
			compatible = "zinitix,bt532_ts_device";
			reg = <0x20>;
			pinctrl-names = "on_state", "off_state";
			pinctrl-0 = <0x1c>;
			pinctrl-1 = <0x1d>;
			zinitix,irq_gpio = <0x1e 0x02 0x00>;
			zinitix,gpio_ldo_en;
			zinitix,regulator_avdd = "tsp_avdd";
			zinitix,x_resolution = <0x21b>;
			zinitix,y_resolution = <0x3bf>;
			zinitix,page_size = <0x40>;
			zinitix,orientation = <0x00>;
			zinitix,chip_name = "BT541C";
			zinitix,firmware_name = "tsp_zinitix/bt541c_gpgo.fw";
			zinitix,touchkey = "true";
		};
	};

	i2c@13830000 {
		compatible = "samsung,s3c2440-i2c";
		reg = <0x00 0x13830000 0x100>;
		interrupts = <0x00 0x1a8 0x00>;
		#address-cells = <0x01>;
		#size-cells = <0x00>;
		pinctrl-names = "default";
		pinctrl-0 = <0x1f>;
		clocks = <0x11 0x136 0x11 0x136>;
		clock-names = "rate_i2c", "gate_i2c";
		status = "disabled";
	};

	i2c@138D0000 {
		compatible = "samsung,s3c2440-i2c";
		reg = <0x00 0x138d0000 0x100>;
		interrupts = <0x00 0x1c5 0x00>;
		#address-cells = <0x01>;
		#size-cells = <0x00>;
		pinctrl-names = "default";
		pinctrl-0 = <0x20>;
		clocks = <0x11 0x12c 0x11 0x12c>;
		clock-names = "rate_i2c", "gate_i2c";
		status = "okay";
		samsung,i2c-sda-delay = <0x64>;
		samsung,i2c-max-bus-freq = <0x61a80>;

		lis2ds@1D {
			compatible = "st,lis2ds";
			reg = <0x1d>;
			pinctrl-names = "default";
			pinctrl-0 = <0x21>;
			interrupt-parent = <0x22>;
			interrupts = <0x02 0x00 0x00>;
			st,orientation = <0x01 0x00 0x01 0x02 0x01 0x01 0x01 0x01 0x00>;
			st,irq_gpio = <0x22 0x02 0x00>;
		};
	};

	i2c@138E0000 {
		compatible = "samsung,s3c2440-i2c";
		reg = <0x00 0x138e0000 0x100>;
		interrupts = <0x00 0x1c6 0x00>;
		#address-cells = <0x01>;
		#size-cells = <0x00>;
		pinctrl-names = "default";
		pinctrl-0 = <0x23>;
		clocks = <0x11 0x12d 0x11 0x12d>;
		clock-names = "rate_i2c", "gate_i2c";
		status = "disabled";
	};

	hsi2c@13950000 {
		compatible = "samsung,exynos5-hsi2c";
		samsung,check-transdone-int;
		reg = <0x00 0x13950000 0x1000>;
		interrupts = <0x00 0x1c9 0x00>;
		#address-cells = <0x01>;
		#size-cells = <0x00>;
		pinctrl-names = "default";
		pinctrl-0 = <0x24>;
		clocks = <0x11 0x14c 0x11 0x14c>;
		clock-names = "rate_hsi2c", "gate_hsi2c";
		samsung,scl-clk-stretching;
		gpio_sda = <0x25 0x01 0x01>;
		gpio_scl = <0x25 0x00 0x01>;
		status = "disabled";
	};

	hsi2c@13960000 {
		compatible = "samsung,exynos5-hsi2c";
		samsung,check-transdone-int;
		reg = <0x00 0x13960000 0x1000>;
		interrupts = <0x00 0x1ca 0x00>;
		#address-cells = <0x01>;
		#size-cells = <0x00>;
		pinctrl-names = "default";
		pinctrl-0 = <0x26>;
		clocks = <0x11 0x14d 0x11 0x14d>;
		clock-names = "rate_hsi2c", "gate_hsi2c";
		samsung,scl-clk-stretching;
		gpio_sda = <0x25 0x03 0x01>;
		gpio_scl = <0x25 0x02 0x01>;
		status = "disabled";
	};

	hsi2c@138A0000 {
		compatible = "samsung,exynos5-hsi2c";
		samsung,check-transdone-int;
		reg = <0x00 0x138a0000 0x1000>;
		interrupts = <0x00 0x1c1 0x00>;
		#address-cells = <0x01>;
		#size-cells = <0x00>;
		pinctrl-names = "default", "on_i2c";
		pinctrl-0 = <0x27>;
		clocks = <0x11 0x141 0x11 0x141>;
		clock-names = "rate_hsi2c", "gate_hsi2c";
		samsung,scl-clk-stretching;
		gpio_sda = <0x28 0x00 0x01>;
		gpio_scl = <0x28 0x01 0x01>;
		status = "okay";
		gpios = <0x28 0x00 0x00 0x28 0x01 0x00>;
		clock-frequency = <0x61a80>;
		pinctrl-1 = <0x27>;

		fimc-is-4h5yc@37 {
			compatible = "samsung,exynos5-fimc-is-cis-4h5yc";
			reg = <0x37>;
			id = <0x00>;
			sensor_f_number = <0x04>;
			setfile = "default";
		};

		fimc-is-5e3@10 {
			compatible = "samsung,exynos5-fimc-is-cis-5e3";
			reg = <0x10>;
			id = <0x01>;
			sensor_f_number = <0x04>;
			setfile = "default";
		};
	};

	hsi2c@138C0000 {
		compatible = "samsung,exynos5-hsi2c";
		samsung,check-transdone-int;
		reg = <0x00 0x138c0000 0x1000>;
		interrupts = <0x00 0x1c3 0x00>;
		#address-cells = <0x01>;
		#size-cells = <0x00>;
		pinctrl-names = "default", "on_i2c";
		pinctrl-0 = <0x29>;
		clocks = <0x11 0x140 0x11 0x140>;
		clock-names = "rate_hsi2c", "gate_hsi2c";
		samsung,scl-clk-stretching;
		gpio_sda = <0x28 0x02 0x01>;
		gpio_scl = <0x28 0x03 0x01>;
		status = "okay";
		gpios = <0x28 0x02 0x00 0x28 0x03 0x00>;
		clock-frequency = <0x61a80>;
		pinctrl-1 = <0x29>;

		rear_eeprom@58 {
			compatible = "samsung,rear-eeprom-i2c";
			reg = <0x58>;
		};

		fimc-is-actuator@0C {
			compatible = "samsung,exynos5-fimc-is-actuator-dw9807";
			reg = <0x0c>;
			id = <0x00>;
		};
	};

	hsi2c@138B0000 {
		compatible = "samsung,exynos5-hsi2c";
		samsung,check-transdone-int;
		reg = <0x00 0x138b0000 0x1000>;
		interrupts = <0x00 0x1c2 0x00>;
		#address-cells = <0x01>;
		#size-cells = <0x00>;
		pinctrl-names = "default";
		pinctrl-0 = <0x2a>;
		clocks = <0x11 0x142 0x11 0x142>;
		clock-names = "rate_hsi2c", "gate_hsi2c";
		samsung,scl-clk-stretching;
		gpio_sda = <0x2b 0x00 0x01>;
		gpio_scl = <0x2b 0x01 0x01>;
		status = "disabled";
	};

	lpass@148F0000 {
		compatible = "samsung,exynos7570-lpass";
		reg = <0x00 0x148f0000 0x1040>;
		clocks = <0x11 0x2e4 0x11 0x2c7 0x11 0x2bf>;
		clock-names = "fout_aud_pll", "dout_sclk_mi2s", "dispaud_decon";
		samsung,syscon-phandle = <0x0f>;
		samsung,power-domain = <0x2c>;
		status = "okay";
	};

	eax {
		compatible = "samsung,exynos-amixer";
		status = "ok";
		linux,phandle = <0x7c>;
		phandle = <0x7c>;
	};

	s1403x@14880000 {
		compatible = "samsung,s1403x";
		reg = <0x00 0x14880000 0x200>;
		clocks = <0x11 0x2e6 0x11 0x2c6>;
		clock-names = "audmixer_dout", "audmixer_aclk";
		samsung,lpass-subip;
		status = "okay";
		pinctrl-names = "default", "idle";
		pinctrl-0 = <0x2d 0x2e>;
		pinctrl-1 = <0x2f>;
		linux,phandle = <0x7e>;
		phandle = <0x7e>;
	};

	i2s@148A0000 {
		compatible = "samsung,i2s-v5";
		reg = <0x00 0x148a0000 0x100>;
		dmas = <0x30 0x1d 0x30 0x1e>;
		dma-names = "tx", "rx";
		interrupts = <0x00 0x45 0x00>;
		clocks = <0x11 0x2c7 0x11 0x2e5 0x11 0x2e5>;
		clock-names = "iis", "i2s_opclk0", "i2s_opclk1";
		samsung,amixer = <0x04>;
		samsung,supports-rstclr;
		samsung,supports-secdai;
		samsung,supports-esa-dma;
		samsung,i2s-str;
		samsung,lpass-subip;
		status = "okay";
		linux,phandle = <0x77>;
		phandle = <0x77>;

		i2s-sec {
			dmas = <0x30 0x1c>;
			dma-names = "tx-sec";
			clocks = <0x11 0x2c7 0x11 0x2e5 0x11 0x2e5>;
			clock-names = "iis", "i2s_opclk0", "i2s_opclk1";
		};
	};

	i2s@148B0000 {
		compatible = "samsung,i2s-v5";
		reg = <0x00 0x148b0000 0x100>;
		dmas = <0x30 0x1f>;
		dma-names = "rx";
		interrupts = <0x00 0x47 0x00>;
		clocks = <0x11 0x2c8 0x11 0x2e5 0x11 0x2e5>;
		clock-names = "iis", "i2s_opclk0", "i2s_opclk1";
		samsung,supports-rstclr;
		samsung,i2s-str;
		samsung,supports-i2s-amp;
		samsung,lpass-subip;
		status = "okay";
		linux,phandle = <0x7b>;
		phandle = <0x7b>;
	};

	hsi2c@13910000 {
		compatible = "samsung,exynos5-hsi2c";
		samsung,check-transdone-int;
		reg = <0x00 0x13910000 0x1000>;
		interrupts = <0x00 0x1cb 0x00>;
		#address-cells = <0x01>;
		#size-cells = <0x00>;
		pinctrl-names = "default";
		pinctrl-0 = <0x31>;
		clocks = <0x11 0x15f 0x11 0x15f>;
		clock-names = "rate_hsi2c", "gate_hsi2c";
		samsung,scl-clk-stretching;
		gpio_sda = <0x19 0x07 0x01>;
		gpio_scl = <0x22 0x00 0x01>;
		status = "disabled";
	};

	hsi2c@13920000 {
		compatible = "samsung,exynos5-hsi2c";
		samsung,check-transdone-int;
		reg = <0x00 0x13920000 0x1000>;
		interrupts = <0x00 0x1cc 0x00>;
		#address-cells = <0x01>;
		#size-cells = <0x00>;
		pinctrl-names = "default";
		pinctrl-0 = <0x32>;
		clocks = <0x11 0x15f 0x11 0x15f>;
		clock-names = "rate_hsi2c", "gate_hsi2c";
		samsung,scl-clk-stretching;
		gpio_sda = <0x22 0x01 0x01>;
		gpio_scl = <0x22 0x02 0x01>;
		status = "disabled";
	};

	hsi2c@13930000 {
		compatible = "samsung,exynos5-hsi2c";
		samsung,check-transdone-int;
		reg = <0x00 0x13930000 0x1000>;
		interrupts = <0x00 0x1cf 0x00>;
		#address-cells = <0x01>;
		#size-cells = <0x00>;
		pinctrl-names = "default";
		pinctrl-0 = <0x33>;
		clocks = <0x11 0x160 0x11 0x160>;
		clock-names = "rate_hsi2c", "gate_hsi2c";
		samsung,scl-clk-stretching;
		gpio_sda = <0x22 0x04 0x01>;
		gpio_scl = <0x22 0x05 0x01>;
		status = "disabled";
	};

	hsi2c@13940000 {
		compatible = "samsung,exynos5-hsi2c";
		samsung,check-transdone-int;
		reg = <0x00 0x13940000 0x1000>;
		interrupts = <0x00 0x1d0 0x00>;
		#address-cells = <0x01>;
		#size-cells = <0x00>;
		pinctrl-names = "default";
		pinctrl-0 = <0x34>;
		clocks = <0x11 0x160 0x11 0x160>;
		clock-names = "rate_hsi2c", "gate_hsi2c";
		samsung,scl-clk-stretching;
		gpio_sda = <0x22 0x06 0x01>;
		gpio_scl = <0x22 0x07 0x01>;
		status = "disabled";
	};

	amba {
		#address-cells = <0x02>;
		#size-cells = <0x01>;
		compatible = "arm,amba-bus";
		interrupt-parent = <0x01>;
		ranges;

		pdma0@10490000 {
			compatible = "arm,pl330", "arm,primecell";
			reg = <0x00 0x10490000 0x1000>;
			interrupts = <0x00 0x17f 0x00>;
			clocks = <0x11 0x32>;
			clock-names = "apb_pclk";
			#dma-cells = <0x01>;
			#dma-channels = <0x08>;
			#dma-requests = <0x20>;
			linux,phandle = <0x30>;
			phandle = <0x30>;
		};
	};

	speedy@10510000 {
		compatible = "samsung,exynos-speedy";
		reg = <0x00 0x10510000 0x2000>;
		interrupts = <0x00 0x174 0x00>;
		#address-cells = <0x01>;
		#size-cells = <0x00>;
		pinctrl-names = "default";
		pinctrl-0 = <0x35>;
		clocks = <0x11 0x0b>;
		clock-names = "gate_speedy";
		status = "okay";
		samsung,always-interrupt-high;

		cod9002x@03 {
			compatible = "codec,cod9002x";
			reg = <0x03>;
			i2c-speedy-address;
			vdd-supply = <0x36>;
			pinctrl-names = "default";
			mic-bias1-voltage = <0x01>;
			mic-bias2-voltage = <0x01>;
			mic-bias-ldo-voltage = <0x03>;
			use-btn-adc-mode;
			use-jack-pullup-mode;
			jack-out-dbnc-time = <0x08>;
			io-channels = <0x37 0x02>;
			io-channel-names = "adc-jack";
			#io-channel-cells = <0x01>;
			io-channel-ranges;
			but-zones-list = <0x38 0xe2 0x00 0x104 0x38 0x246 0x105 0x150 0x38 0x73 0x151 0x214 0x38 0x72 0x215 0x451>;
			mic-adc-range = <0x53c>;
			btn-press-delay = <0x00>;
			linux,phandle = <0x3b>;
			phandle = <0x3b>;
		};

		s2mpu06mfd@00 {
			compatible = "samsung,s2mpu06mfd";
			reg = <0x00>;
			pinctrl-names = "default";
			pinctrl-0 = <0x39>;
			s2mpu06,wakeup = "enabled";
			s2mpu06,irq-gpio = <0x3a 0x05 0x00>;
			i2c-speedy-address;
			cache_data = <0x01>;
			wtsr_en = "enabled";
			smpl_en = "enabled";
			wtsr_timer_val = <0x03>;
			smpl_timer_val = <0x00>;
			check_jigon = <0x00>;
			init_time,sec = <0x00>;
			init_time,min = <0x00>;
			init_time,hour = <0x0c>;
			init_time,mday = <0x01>;
			init_time,mon = <0x00>;
			init_time,year = <0x76>;
			init_time,wday = <0x01>;
			samsung,codec-interrupt = <0x3b>;

			s2mpu06-keys {

				button@1 {
					label = "pmic-keys: KEY_POWER";
					linux,code = <0x74>;
					wakeup = <0x01>;
				};
			};

			regulators {

				BUCK2 {
					regulator-name = "BUCK2";
					regulator-min-microvolt = "", "\f5";
					regulator-max-microvolt = <0x2ab980>;
					regulator-always-on;
					regulator-boot-on;
					regulator-ramp-delay = <0x2ee0>;
					regulator-initial-mode = <0x03>;
				};

				BUCK3 {
					regulator-name = "BUCK3";
					regulator-min-microvolt = "", "\f5";
					regulator-max-microvolt = <0x2ab980>;
					regulator-always-on;
					regulator-boot-on;
					regulator-ramp-delay = <0x2ee0>;
					regulator-initial-mode = <0x03>;
				};

				LDO1 {
					regulator-name = "vdd_ldo1";
					regulator-min-microvolt = <0x7a120>;
					regulator-max-microvolt = <0x13d620>;
					regulator-always-on;
					regulator-boot-on;
					regulator-ramp-delay = <0x2ee0>;
					regulator-initial-mode = <0x01>;
				};

				LDO2 {
					regulator-name = "vdd_ldo2";
					regulator-min-microvolt = <0x16e360>;
					regulator-max-microvolt = <0x1e8480>;
					regulator-boot-on;
					regulator-always-on;
					regulator-ramp-delay = <0x2ee0>;
					regulator-initial-mode = <0x03>;
				};

				LDO3 {
					regulator-name = "vdd_ldo3";
					regulator-min-microvolt = "", "\f5";
					regulator-max-microvolt = <0x16e360>;
					regulator-boot-on;
					regulator-always-on;
					regulator-ramp-delay = <0x2ee0>;
					regulator-initial-mode = <0x03>;
				};

				LDO4 {
					regulator-name = "vqmmc";
					regulator-min-microvolt = <0x19f0a0>;
					regulator-max-microvolt = <0x331df0>;
					regulator-ramp-delay = <0x2ee0>;
					regulator-initial-mode = <0x00>;
				};

				LDO5 {
					regulator-name = "vdd_ldo5";
					regulator-min-microvolt = <0x19f0a0>;
					regulator-max-microvolt = <0x331df0>;
					regulator-boot-on;
					regulator-always-on;
					regulator-ramp-delay = <0x2ee0>;
					regulator-initial-mode = <0x03>;
				};

				LDO6 {
					regulator-name = "vdd_ldo6";
					regulator-min-microvolt = <0x7a120>;
					regulator-max-microvolt = <0x13d620>;
					regulator-boot-on;
					regulator-always-on;
					regulator-ramp-delay = <0x2ee0>;
					regulator-initial-mode = <0x03>;
				};

				LDO7 {
					regulator-name = "vdd_ldo7";
					regulator-min-microvolt = "", "\f5";
					regulator-max-microvolt = <0x13d620>;
					regulator-boot-on;
					regulator-always-on;
					regulator-ramp-delay = <0x2ee0>;
					regulator-initial-mode = <0x01>;
				};

				LDO8 {
					regulator-name = "vdd_ldo8";
					regulator-min-microvolt = <0x1b7740>;
					regulator-max-microvolt = <0x337f98>;
					regulator-boot-on;
					regulator-always-on;
					regulator-ramp-delay = <0x2ee0>;
					regulator-initial-mode = <0x01>;
				};

				LDO13 {
					regulator-name = "vdd_ldo13";
					regulator-min-microvolt = "", "\f5";
					regulator-max-microvolt = <0x1e8480>;
					regulator-ramp-delay = <0x2ee0>;
					regulator-always-on;
					regulator-boot-on;
					regulator-initial-mode = <0x03>;
					linux,phandle = <0x36>;
					phandle = <0x36>;
				};

				LDO14 {
					regulator-name = "vemmc";
					regulator-min-microvolt = <0x1b7740>;
					regulator-max-microvolt = <0x337f98>;
					regulator-ramp-delay = <0x2ee0>;
					regulator-initial-mode = <0x00>;
				};

				LDO15 {
					regulator-name = "vqemmc";
					regulator-min-microvolt = "", "\f5";
					regulator-max-microvolt = <0x1e8480>;
					regulator-ramp-delay = <0x2ee0>;
					regulator-initial-mode = <0x00>;
				};

				LDO17 {
					regulator-name = "VDD18_CAM_SENSOR_IO";
					regulator-min-microvolt = <0x1b7740>;
					regulator-max-microvolt = <0x1b7740>;
					regulator-ramp-delay = <0x2ee0>;
					regulator-initial-mode = <0x00>;
				};

				LDO18 {
					regulator-name = "VDD28_CAM_AF";
					regulator-min-microvolt = <0x2ab980>;
					regulator-max-microvolt = <0x2ab980>;
					regulator-ramp-delay = <0x2ee0>;
					regulator-initial-mode = <0x00>;
				};

				LDO19 {
					regulator-name = "vtouch_2.2v";
					regulator-min-microvolt = <0x2191c0>;
					regulator-max-microvolt = <0x2191c0>;
					regulator-boot-on;
				};

				LDO21 {
					regulator-name = "vdd_ldo21";
					regulator-min-microvolt = <0x1b7740>;
					regulator-max-microvolt = <0x337f98>;
					regulator-ramp-delay = <0x2ee0>;
					regulator-initial-mode = <0x00>;
				};

				LDO22 {
					regulator-name = "vdd_ldo22";
					regulator-min-microvolt = <0x1b7740>;
					regulator-max-microvolt = <0x337f98>;
					regulator-always-on;
					regulator-ramp-delay = <0x2ee0>;
					regulator-initial-mode = <0x03>;
				};

				LDO24 {
					regulator-name = "AVDD24_CAM_2P8";
					regulator-min-microvolt = <0x2ab980>;
					regulator-max-microvolt = <0x2ab980>;
					regulator-ramp-delay = <0x2ee0>;
					regulator-initial-mode = <0x00>;
				};

				BUCK1 {
					regulator-name = "BUCK1";
					regulator-min-microvolt = <0x7a120>;
					regulator-max-microvolt = <0x13d620>;
					regulator-always-on;
					regulator-boot-on;
					regulator-ramp-delay = <0x2ee0>;
					regulator-initial-mode = <0x01>;
					regulator-expected-consumer = <0x06>;
				};

				LDO16 {
					regulator-name = "VDD_MOTOR_3P3";
					regulator-min-microvolt = <0x325aa0>;
					regulator-max-microvolt = <0x325aa0>;
					regulator-ramp-delay = <0x2ee0>;
					regulator-initial-mode = <0x00>;
				};

				LDO23 {
					regulator-name = "VDD_23";
					regulator-min-microvolt = <0x124f80>;
					regulator-max-microvolt = <0x124f80>;
					regulator-ramp-delay = <0x2ee0>;
					regulator-initial-mode = <0x00>;
				};
			};
		};

		fimc_is_flash@06 {
			compatible = "samsung,sensor-flash-i2c";
			reg = <0x06>;
			id = <0x00>;
			flash-gpio = <0x3a 0x00 0x00>;
			flash_current = <0x3e8>;
			preflash_current = <0xa0>;
			movie_current = <0xa0>;
			torch_current = <0x50>;
			factory_current = <0xa0>;
			torch_level1 = <0x00>;
			torch_level2 = <0x01>;
			torch_level3 = <0x02>;
			torch_level4 = <0x03>;
			torch_level5 = <0x06>;
			i2c-speedy-address;
		};
	};

	spi@100C0000 {
		compatible = "samsung,exynos-spi";
		reg = <0x00 0x100c0000 0x100>;
		samsung,spi-fifosize = <0x100>;
		interrupts = <0x00 0x1b2 0x00>;
		dma-names = "tx", "rx";
		swap-mode;
		#address-cells = <0x01>;
		#size-cells = <0x00>;
		clocks = <0x11 0x16a 0x11 0x17>;
		clock-names = "spi", "spi_busclk0";
		pinctrl-names = "default";
		pinctrl-0 = <0x3c>;
		status = "disabled";
	};

	spi@13900000 {
		compatible = "samsung,exynos-spi";
		reg = <0x00 0x13900000 0x100>;
		samsung,spi-fifosize = <0x40>;
		interrupts = <0x00 0x1b1 0x00>;
		dma-names = "tx", "rx";
		swap-mode;
		#address-cells = <0x01>;
		#size-cells = <0x00>;
		clocks = <0x11 0x16b 0x11 0x16>;
		clock-names = "spi", "spi_busclk0";
		pinctrl-names = "default";
		pinctrl-0 = <0x3d>;
		status = "disabled";
	};

	spi@13910000 {
		compatible = "samsung,exynos-spi";
		reg = <0x00 0x13910000 0x100>;
		samsung,spi-fifosize = <0x20>;
		interrupts = <0x00 0x1ce 0x00>;
		dma-names = "tx", "rx";
		swap-mode;
		#address-cells = <0x01>;
		#size-cells = <0x00>;
		clocks = <0x11 0x15f 0x11 0x28>;
		clock-names = "spi", "spi_busclk0";
		pinctrl-names = "default";
		pinctrl-0 = <0x3e>;
		status = "disabled";
	};

	spi@13930000 {
		compatible = "samsung,exynos-spi";
		reg = <0x00 0x13930000 0x100>;
		samsung,spi-fifosize = <0x20>;
		interrupts = <0x00 0x1d2 0x00>;
		dma-names = "tx", "rx";
		swap-mode;
		#address-cells = <0x01>;
		#size-cells = <0x00>;
		clocks = <0x11 0x160 0x11 0x29>;
		clock-names = "spi", "spi_busclk0";
		pinctrl-names = "default";
		pinctrl-0 = <0x3f>;
		status = "disabled";
	};

	secgpio_dvs {
		compatible = "samsung,exynos7570-secgpio-dvs";
		status = "okay";
	};

	dwmmc0@13540000 {
		compatible = "samsung,exynos-dw-mshc";
		reg = <0x00 0x13540000 0x2000>;
		interrupts = <0x00 0xf5 0x00>;
		#address-cells = <0x01>;
		#size-cells = <0x00>;
		clocks = <0x11 0x201 0x11 0x203 0x11 0x1e>;
		clock-names = "biu", "ciu", "ciu_gate";
		status = "okay";
		num-slots = <0x01>;
		broken-card-detect;
		use-smu;
		fixed_voltage;
		supports-highspeed;
		clock-gate;
		mmc-ddr-1_8v;
		mmc-hs200-1_8v;
		mmc-hs400-1_8v;
		supports-8bit;
		supports-cmd23;
		supports-erase;
		enable-ulp-mode;
		supports-hs400-enhanced-strobe;
		pm-skip-mmc-resume-init;
		mmc_pwr_shut_down;
		card-init-hwacg-ctrl;
		fifo-depth = <0x40>;
		non-removable;
		desc-size = <0x04>;
		card-detect-delay = <0xc8>;
		data-timeout = <0xc8>;
		hto-timeout = <0x50>;
		clock-frequency = <0x29b92700>;
		samsung,dw-mshc-ciu-div = <0x03>;
		samsung,dw-mshc-txdt-crc-timer-fastlimit = <0x34>;
		samsung,dw-mshc-txdt-crc-timer-initval = <0x38>;
		samsung,dw-mshc-ddr200-delay-line = <0x60>;
		samsung,dw-mshc-sdr-timing = <0x03 0x00 0x02 0x00>;
		samsung,dw-mshc-ddr-timing = <0x03 0x00 0x04 0x02>;
		samsung,dw-mshc-hs200-timing = <0x03 0x00 0x03 0x00>;
		samsung,dw-mshc-ddr200-timing = <0x01 0x00 0x04 0x00>;
		samsung,dw-mshc-ddr200-ulp-timing = <0x03 0x00 0x03 0x00>;
		num-ref-clks = <0x0c>;
		ciu_clkin = <0x19 0x2b 0x2b 0x19 0x2b 0x57 0xaf 0x2b 0x2b 0xaf 0xaf 0xaf>;
		clk-drive-number = <0x04>;
		pinctrl-names = "default", "fast-slew-rate-1x", "fast-slew-rate-2x", "fast-slew-rate-3x", "fast-slew-rate-4x";
		pinctrl-0 = <0x40 0x41 0x42 0x43 0x44 0x45>;
		pinctrl-1 = <0x46>;
		pinctrl-2 = <0x47>;
		pinctrl-3 = <0x48>;
		pinctrl-4 = <0x49>;

		slot@0 {
			reg = <0x00>;
			bus-width = <0x08>;
		};
	};

	dwmmc2@13560000 {
		compatible = "samsung,exynos-dw-mshc";
		reg = <0x00 0x13560000 0x2000>;
		interrupts = <0x00 0xf7 0x00>;
		#address-cells = <0x01>;
		#size-cells = <0x00>;
		clocks = <0x11 0x202 0x11 0x204 0x11 0x1f>;
		clock-names = "biu", "ciu", "ciu_gate";
		status = "okay";
		num-slots = <0x01>;
		clock-gate;
		supports-highspeed;
		supports-4bit;
		supports-cmd23;
		supports-erase;
		sd-uhs-sdr50;
		sd-uhs-sdr104;
		card-detect-gpio;
		bypass-smu;
		only_once_tune;
		bypass-for-allpass;
		use-fine-tuning;
		skip-init-mmc-scan;
		card-init-hwacg-ctrl;
		switch_transfer;
		ignore-phase = <0x80>;
		fifo-depth = <0x40>;
		desc-size = <0x04>;
		card-detect-delay = <0xc8>;
		data-timeout = <0xc8>;
		hto-timeout = <0x50>;
		clock-frequency = <0x29b92700>;
		samsung,dw-mshc-ciu-div = <0x03>;
		samsung,dw-mshc-sdr-timing = <0x03 0x00 0x02 0x00>;
		samsung,dw-mshc-ddr-timing = <0x03 0x00 0x02 0x01>;
		samsung,dw-mshc-sdr50-timing = <0x03 0x00 0x04 0x02>;
		samsung,dw-mshc-sdr104-timing = <0x03 0x00 0x03 0x00>;
		num-ref-clks = <0x09>;
		ciu_clkin = <0x19 0x2b 0x2b 0x19 0x2b 0x57 0xaf 0x2b 0x2b>;
		clk-drive-number = <0x04>;
		pinctrl-names = "default", "fast-slew-rate-1x", "fast-slew-rate-2x", "fast-slew-rate-3x", "fast-slew-rate-4x";
		pinctrl-0 = <0x4a 0x4b 0x4c 0x4d 0x4e 0x4f>;
		pinctrl-1 = <0x50>;
		pinctrl-2 = <0x51>;
		pinctrl-3 = <0x52>;
		pinctrl-4 = <0x53>;
		card-detect = <0x3a 0x01 0x0f>;
		sec-sd-slot-type = <0x01>;

		slot@0 {
			reg = <0x00>;
			bus-width = <0x04>;
			disable-wp;
		};
	};

	mali@11400000 {
		compatible = "arm,mali";
		reg = <0x00 0x11400000 0x5000>;
		interrupts = <0x00 0x11a 0x00 0x00 0x11b 0x00 0x00 0x119 0x00>;
		interrupt-names = "JOB", "MMU", "GPU";
		clocks = <0x11 0xcb>;
		clock-names = "vclk_g3d";
		samsung,power-domain = <0x0d>;
	};

	mfc0@12C30000 {
		compatible = "samsung,mfc-v6";
		#pb-id-cells = <0x00>;
		reg = <0x00 0x12c30000 0x10000>;
		interrupts = <0x00 0x162 0x00>;
		clock-names = "aclk_mfc";
		clocks = <0x11 0x264>;
		samsung,power-domain = <0x0a>;
		status = "ok";
		ip_ver = <0x11>;
		clock_rate = <0x18bc65c0>;
		min_rate = <0x186a0>;
		num_qos_steps = <0x02>;
		linux,phandle = <0x5b>;
		phandle = <0x5b>;

		mfc_qos_table {

			mfc_qos_variant_0 {
				thrd_mb = <0x00>;
				freq_mfc = <0x00>;
				freq_int = <0x65518>;
				freq_mif = <0x65518>;
				freq_cpu = <0x00>;
				freq_kfc = <0x00>;
				has_enc_table = <0x00>;
			};

			mfc_qos_variant_1 {
				thrd_mb = <0x3bc40>;
				freq_mfc = <0x00>;
				freq_int = <0x65518>;
				freq_mif = <0xa2990>;
				freq_cpu = <0x00>;
				freq_kfc = <0x00>;
				has_enc_table = <0x00>;
			};
		};
	};

	phy_m4s4_dsi@148F100C {
		compatible = "samsung,mipi-phy-dsim";
		reg = <0x00 0x148f100c 0x04>;
		samsung,pmu-syscon = <0x0f>;
		isolation = <0x70c>;
		reset = <0x00>;
		#phy-cells = <0x01>;
		linux,phandle = <0x55>;
		phandle = <0x55>;
	};

	mdev_output {
		compatible = "samsung,exynos5-mdev";
	};

	dsim@14800000 {
		compatible = "samsung,exynos8-mipi-dsi";
		reg = <0x00 0x14800000 0x100>;
		interrupts = <0x00 0xcf 0x00>;
		samsung,power-domain = <0x54>;
		phys = <0x55 0x00>;
		phy-names = "dsim_dphy";
		clocks = <0x11 0x2c0 0x11 0x2d1 0x11 0x2d0>;
		clock-names = "dsim_pclk", "dphy_escclk", "dphy_byteclk";
		data_lane_cnt = <0x02>;
		lcd_info = <0x56>;
		decon_board = <0x57>;
		status = "okay";
	};

	decon_fb@14830000 {
		compatible = "samsung,exynos5-decon_driver";
		#address-cells = <0x02>;
		#size-cells = <0x01>;
		ranges;
		reg = <0x00 0x14830000 0x8000>;
		#pb-id-cells = <0x00>;
		samsung,power-domain = <0x54>;
		interrupts = <0x00 0xc9 0x00 0x00 0xca 0x00 0x00 0xcb 0x00 0x00 0x168 0x00>;
		clocks = <0x11 0x2bf 0x11 0x2da 0x11 0x2db>;
		clock-names = "decon_core", "vclk_user", "vclk_leaf";
		ip_ver = <0x04>;
		max_win = <0x03>;
		n_sink_pad = <0x03>;
		n_src_pad = <0x01>;
		default_win = <0x00>;
		trig_mode = <0x01>;
		dsi_mode = <0x00>;
		psr_mode = <0x00>;
		mif-vclk = <0xbebc200>;
		disp-vclk = <0xbebc200>;
		vclk-num = <0x400>;
		vclk-denom = <0x189>;
		disp-dvfs = <0xc65d400>;
		linux,phandle = <0x5f>;
		phandle = <0x5f>;
	};

	mcu_ipc@10500000 {
		compatible = "samsung,exynos-shd-ipc-mailbox";
		reg = <0x00 0x10500000 0x180>;
		mcu,name = "mcu_ipc_cp";
		mcu,id = <0x00>;
		interrupts = <0x00 0x171 0x00>;
		mcu,irq_affinity_mask = <0x03>;
	};

	mcu_ipc@10570000 {
		compatible = "samsung,exynos-shd-ipc-mailbox";
		reg = <0x00 0x10570000 0x180>;
		mcu,name = "mcu_ipc_gnss";
		mcu,id = <0x01>;
		interrupts = <0x00 0x175 0x00>;
	};

	gnss_pdata {
		compatible = "samsung,gnss_shdmem_if";
		shmem,name = "KEPLER";
		shmem,device_node_name = "gnss_ipc";
		status = "okay";
		interrupts = <0x00 0x13 0x00 0x00 0x1de 0x00 0x00 0x1dd 0x00>;
		mbx,int_ap2gnss_bcmd = <0x00>;
		mbx,int_ap2gnss_req_fault_info = <0x01>;
		mbx,int_ap2gnss_ipc_msg = <0x02>;
		mbx,int_ap2gnss_ack_wake_set = <0x03>;
		mbx,int_ap2gnss_ack_wake_clr = <0x04>;
		mbx,irq_gnss2ap_bcmd = <0x00>;
		mbx,irq_gnss2ap_rsp_fault_info = <0x01>;
		mbx,irq_gnss2ap_ipc_msg = <0x02>;
		mbx,irq_gnss2ap_req_wake_clr = <0x04>;
		mbx,reg_bcmd_ctrl = <0x00 0x01 0x02 0x03>;
		reg_rx_ipc_msg = <0x01 0x05>;
		reg_tx_ipc_msg = <0x01 0x04>;
		reg_rx_head = <0x01 0x03>;
		reg_rx_tail = <0x01 0x02>;
		reg_tx_head = <0x01 0x01>;
		reg_tx_tail = <0x01 0x00>;
		fault_info = <0x01 0x100000 0x100000>;
		shmem,ipc_offset = <0x180000>;
		shmem,ipc_size = <0x80000>;
		shmem,ipc_reg_cnt = <0x20>;
	};

	cmu_fsys@0x13730000 {
		compatible = "samsung,exynos7570-cmu_fsys", "syscon";
		reg = <0x00 0x13730000 0x2000>;
		linux,phandle = <0x58>;
		phandle = <0x58>;
	};

	scsc_wifibt@10580000 {
		compatible = "samsung,scsc_wifibt";
		reg = <0x00 0x10580000 0x180>;
		interrupts = <0x00 0x178 0x04 0x00 0x15 0x04 0x00 0x1dc 0x04>;
		interrupt-names = "MBOX", "ALIVE", "WDOG";
		samsung,syscon-phandle = <0x0f>;
		samsung,syscon-cmu_fsys = <0x58>;
		usbpll,owner = "y";
		usbpll,udelay = <0x14>;
		status = "okay";
	};

	iommu-domain_mfc_mscl {
		compatible = "samsung,exynos-iommu-bus";
		#address-cells = <0x02>;
		#size-cells = <0x01>;
		domain-clients = <0x59 0x5a 0x5b 0x5c 0x5d 0x5e>;
		ranges;

		smfc@12C20000 {
			compatible = "samsung,exynos8890-jpeg";
			reg = <0x00 0x12c20000 0x2000>;
			interrupts = <0x00 0x194 0x00>;
			clocks = <0x11 0x263>;
			clock-names = "gate";
			samsung,power-domain = <0x0a>;
			linux,phandle = <0x59>;
			phandle = <0x59>;
		};

		scaler@12C10000 {
			compatible = "samsung,exynos5-scaler";
			reg = <0x00 0x12c10000 0x1300>;
			interrupts = <0x00 0x191 0x00>;
			clocks = <0x11 0x262>;
			clock-names = "gate";
			samsung,power-domain = <0x0a>;
			prefetch-buffer,disable;
			linux,phandle = <0x5a>;
			phandle = <0x5a>;
		};

		sysmmu@12C80000 {
			compatible = "samsung,exynos7420-sysmmu";
			reg = <0x00 0x12c80000 0x3000>;
			interrupts = <0x00 0x160 0x00 0x00 0x199 0x00>;
			clocks = <0x11 0x44c>;
			clock-names = "aclk";
			samsung,power-domain = <0x0a>;
			sysmmu,v7tlb_property = <0x02 0x4a 0x06 0x4a 0x0e 0x46 0x8022 0x46 0x8026 0x46 0x802a 0x46>;
			sysmmu,secure_reg = <0x12c70000>;
			sysmmu,handle_secure-irq;
			master_ip_list = <0x59 0x5a 0x5b 0x5c>;
		};

		sysmmu@0x14470000 {
			compatible = "samsung,exynos7420-sysmmu";
			reg = <0x00 0x14470000 0x3000>;
			interrupts = <0x00 0x80 0x00>;
			qos = <0x0f>;
			clocks = <0x11 0x44e>;
			clock-names = "aclk";
			samsung,power-domain = <0x0c>;
			sysmmu,v7tlb_property = <0x8000 0x0a 0x8004 0x0a 0x01 0x0a 0x8001 0x0a 0x8005 0x0a 0x8002 0x0a 0x8006 0x0a 0x800a 0x0a 0x8003 0x0a 0x03 0x20>;
			master_ip_list = <0x5c 0x5d 0x5e>;
		};
	};

	iommu-domain_disp {
		compatible = "samsung,exynos-iommu-bus";
		#address-cells = <0x02>;
		#size-cells = <0x01>;
		ranges;
		domain-clients = <0x5f>;

		sysmmu@14860000 {
			compatible = "samsung,exynos7420-sysmmu";
			reg = <0x00 0x14860000 0x3000>;
			interrupts = <0x00 0xc0 0x00 0x00 0xc1 0x00>;
			qos = <0x0f>;
			clocks = <0x11 0x44d>;
			clock-names = "aclk";
			samsung,power-domain = <0x0b>;
			sysmmu,v7tlb_property = <0x00 0x00 0x02 0x00 0x04 0x00 0x05 0x00>;
			sysmmu,secure_reg = <0x14850000>;
			sysmmu,handle_secure-irq;
			master_ip_list = <0x5f>;
		};
	};

	watchdog@10170000 {
		compatible = "samsung,exynos7-wdt";
		reg = <0x00 0x10170000 0x100>;
		interrupts = <0x00 0x64 0x00>;
		clocks = <0x11 0x173 0x11 0x173>;
		clock-names = "rate_watchdog", "gate_watchdog";
		timeout-sec = <0x1e>;
		samsung,syscon-phandle = <0x0f>;
	};

	adc@10550000 {
		compatible = "samsung,exynos-adc-v3";
		reg = <0x00 0x10550000 0x1000>;
		interrupts = <0x00 0x18b 0x00>;
		#io-channel-cells = <0x01>;
		io-channel-ranges;
		clocks = <0x11 0x0a>;
		clock-names = "gate_adcif";
		linux,phandle = <0x37>;
		phandle = <0x37>;
	};

	rtc@101A0000 {
		compatible = "samsung,s3c6410-rtc";
		reg = <0x00 0x101a0000 0x100>;
		interrupts = <0x00 0x5c 0x00 0x00 0x5d 0x00>;
		clocks = <0x11 0x176>;
		clock-names = "gate_rtc";
	};

	coresight@16000000 {
		compatible = "exynos,coresight";
		base = <0x16000000>;
		sjtag-offset = <0x6000>;

		cs_apollo0@400000 {
			device_type = "cs";
			dbg-offset = <0x410000>;
		};

		cs_apollo1@500000 {
			device_type = "cs";
			dbg-offset = <0x510000>;
		};

		cs_apollo2@600000 {
			device_type = "cs";
			dbg-offset = <0x610000>;
		};

		cs_apollo3@700000 {
			device_type = "cs";
			dbg-offset = <0x710000>;
		};
	};

	usb@13600000 {
		compatible = "samsung,exynos7570-dwusb2";
		reg = <0x00 0x13600000 0x10000>;
		clocks = <0x11 0x200>;
		clock-names = "usbdrd20";
		#address-cells = <0x02>;
		#size-cells = <0x01>;
		ranges;
		status = "okay";
		linux,phandle = <0x6b>;
		phandle = <0x6b>;

		dwc3 {
			compatible = "synopsys,dwc3";
			reg = <0x00 0x13600000 0x10000>;
			interrupts = <0x00 0xe6 0x00>;
			maximum-speed = "high-speed";
			is_not_vbus_pad;
			suspend_clk_freq = <0x3fe56c0>;
			enable_sprs_transfer;
			phys = <0x60 0x00 0x60 0x01>;
			phy-names = "usb2-phy", "usb3-phy";
			dr_mode = "otg";
		};
	};

	usbphy@135c0000 {
		compatible = "samsung,exynos7570-usbdrd-phy";
		reg = <0x00 0x135c0000 0x100>;
		clocks = <0x11 0x200 0x11 0x208 0x11 0x212>;
		clock-names = "usbdrd20", "phyumux", "usb_pll";
		#phy-cells = <0x01>;
		samsung,pmu-syscon = <0x0f>;
		is_not_vbus_pad;
		use_additional_tuning;
		request_extrefclk;
		uart_io_share_enable = <0x01>;
		uart_io_share_offset = <0x6200>;
		uart_io_share_mask = <0x01>;
		status = "okay";
		hs_tune_info = <0x61>;
		ss_tune_info = <0x62>;
		linux,phandle = <0x60>;
		phandle = <0x60>;
	};

	pwm@13970000 {
		compatible = "samsung,s3c6400-pwm";
		reg = <0x00 0x13970000 0x1000>;
		samsung,pwm-outputs = <0x00 0x01 0x02 0x03 0x04>;
		samsung,pwm-sclk-ctrl;
		#pwm-cells = <0x03>;
		clocks = <0x11 0x14a 0x11 0x14b 0x63 0x01 0x63 0x02 0x63 0x05 0x63 0x06 0x63 0x07 0x63 0x08 0x63 0x0a 0x63 0x0b 0x63 0x0c 0x63 0x0d>;
		clock-names = "gate_timers", "sclk_pwm", "pwm-scaler0", "pwm-scaler1", "pwm-tdiv0", "pwm-tdiv1", "pwm-tdiv2", "pwm-tdiv3", "pwm-tin0", "pwm-tin1", "pwm-tin2", "pwm-tin3";
		status = "ok";
	};

	pwm-clock-controller@13970000 {
		compatible = "samsung,exynos-pwm-clock";
		reg = <0x00 0x13970000 0x50>;
		#clock-cells = <0x01>;
		linux,phandle = <0x63>;
		phandle = <0x63>;
	};

	phy_phy_csis@144F1040 {
		compatible = "samsung,mipi-phy-csis";
		reg = <0x00 0x144f1040 0x04>;
		samsung,pmu-syscon = <0x0f>;
		isolation = <0x70c 0x714>;
		reset = <0x01 0x00>;
		#phy-cells = <0x01>;
		linux,phandle = <0x64>;
		phandle = <0x64>;
	};

	fimc_is_sensor0@14420000 {
		compatible = "samsung,exynos5-fimc-is-sensor";
		#pb-id-cells = <0x00>;
		reg = <0x00 0x14420000 0x10000 0x00 0x14410000 0x10000>;
		interrupts = <0x00 0x90 0x00 0x00 0x89 0x00>;
		samsung,power-domain = <0x0c>;
		phys = <0x64 0x01>;
		phy-names = "csis_dphy";
		clock-names = "mif_isp_sensor0";
		clocks = <0x11 0x2b>;
		scenario = <0x00>;
		id = <0x00>;
		csi_ch = <0x00>;
		flite_ch = <0x00>;
		is_bns = <0x01>;
		status = "okay";
		linux,phandle = <0x5d>;
		phandle = <0x5d>;
	};

	fimc_is_sensor1@14420000 {
		compatible = "samsung,exynos5-fimc-is-sensor";
		#pb-id-cells = <0x00>;
		reg = <0x00 0x14420000 0x10000 0x00 0x14410000 0x10000>;
		interrupts = <0x00 0x90 0x00 0x00 0x89 0x00>;
		samsung,power-domain = <0x0c>;
		phys = <0x64 0x00>;
		phy-names = "csis_dphy";
		clock-names = "mif_isp_sensor0";
		clocks = <0x11 0x2b>;
		scenario = <0x00>;
		id = <0x01>;
		csi_ch = <0x00>;
		flite_ch = <0x00>;
		is_bns = <0x01>;
		status = "okay";
		linux,phandle = <0x5e>;
		phandle = <0x5e>;
	};

	fimc_is@14400000 {
		compatible = "samsung,exynos5-fimc-is";
		#pb-id-cells = <0x00>;
		reg = <0x00 0x14400000 0xc400 0x00 0x14430000 0x2000 0x00 0x14440000 0x10000 0x00 0x14450000 0x10000 0x00 0x14480000 0xc400 0x00 0x12c00000 0x2000>;
		interrupts = <0x00 0x8b 0x00 0x00 0x8c 0x00 0x00 0x8d 0x00 0x00 0x8e 0x00 0x00 0x92 0x00 0x00 0x190 0x00>;
		samsung,power-domain = <0x0c>;
		clock-names = "oscclk", "isp_ppmu", "isp_bts", "isp_cam", "isp_vra", "umux_isp_clkphy_isp_s_rxbyteclkhs0_s4_user", "gate_mscl", "mif_isp_sensor0";
		clocks = <0x11 0x01 0x11 0x321 0x11 0x322 0x11 0x323 0x11 0x324 0x11 0x32a 0x11 0x262 0x11 0x2b>;
		status = "ok";
		linux,phandle = <0x5c>;
		phandle = <0x5c>;

		vender {
			rear_sensor_id = <0x18>;
			front_sensor_id = <0x11>;
			use_module_check;
			total_camera_num = <0x02>;

			camera_info0 {
				isp = <0x00>;
				cal_memory = <0x02>;
				read_version = <0x00>;
				core_voltage = <0x00>;
				upgrade = <0x00>;
				companion = <0x00>;
				ois = <0x00>;
			};

			camera_info1 {
				isp = <0x00>;
				cal_memory = <0x03>;
				read_version = <0x00>;
				core_voltage = <0x00>;
				upgrade = <0x00>;
				companion = <0x00>;
				ois = <0x00>;
			};
		};

		fimc_is_dvfs {

			table0 {
				desc = "HAL1 version";
				default_int = <0x72038>;
				default_cam = <0x87410>;
				default_mif = <0xcaa30>;
				default_i2c = <0x00>;
				front_preview_int = <0x72038>;
				front_preview_cam = <0x6c660>;
				front_preview_mif = <0xcaa30>;
				front_preview_i2c = <0x00>;
				front_capture_int = <0x72038>;
				front_capture_cam = <0x6c660>;
				front_capture_mif = <0xcaa30>;
				front_capture_i2c = <0x00>;
				front_video_int = <0x72038>;
				front_video_cam = <0x6c660>;
				front_video_mif = <0xcaa30>;
				front_video_i2c = <0x00>;
				front_video_capture_int = <0x72038>;
				front_video_capture_cam = <0x6c660>;
				front_video_capture_mif = <0xcaa30>;
				front_video_capture_i2c = <0x00>;
				front_vt1_int = <0x72038>;
				front_vt1_cam = <0x6c660>;
				front_vt1_mif = <0xcaa30>;
				front_vt1_i2c = <0x00>;
				front_vt2_int = <0x72038>;
				front_vt2_cam = <0x6c660>;
				front_vt2_mif = <0xcaa30>;
				front_vt2_i2c = <0x00>;
				rear_preview_int = <0x72038>;
				rear_preview_cam = <0x87410>;
				rear_preview_mif = <0xcaa30>;
				rear_preview_i2c = <0x00>;
				rear_capture_int = <0x72038>;
				rear_capture_cam = <0x87410>;
				rear_capture_mif = <0xcaa30>;
				rear_capture_i2c = <0x00>;
				rear_video_int = <0x72038>;
				rear_video_cam = <0x87410>;
				rear_video_mif = <0xcaa30>;
				rear_video_i2c = <0x00>;
				rear_video_capture_int = <0x72038>;
				rear_video_capture_cam = <0x87410>;
				rear_video_capture_mif = <0xcaa30>;
				rear_video_capture_i2c = <0x00>;
				preview_high_speed_fps_int = <0x72038>;
				preview_high_speed_fps_cam = <0x87410>;
				preview_high_speed_fps_mif = <0xcaa30>;
				preview_high_speed_fps_i2c = <0x00>;
				video_high_speed_60fps_int = <0x72038>;
				video_high_speed_60fps_cam = <0x87410>;
				video_high_speed_60fps_mif = <0xcaa30>;
				video_high_speed_60fps_i2c = <0x00>;
				video_high_speed_120fps_int = <0x72038>;
				video_high_speed_120fps_cam = <0x87410>;
				video_high_speed_120fps_mif = <0xcaa30>;
				video_high_speed_120fps_i2c = <0x00>;
				max_int = <0x72038>;
				max_cam = <0xa2990>;
				max_mif = <0xcaa30>;
				max_i2c = <0x00>;
			};

			table1 {
				desc = "HAL3 version";
				default_int = <0x72038>;
				default_cam = <0x87410>;
				default_mif = <0xcaa30>;
				default_i2c = <0x00>;
				front_preview_int = <0x72038>;
				front_preview_cam = <0x6c660>;
				front_preview_mif = <0xcaa30>;
				front_preview_i2c = <0x00>;
				front_capture_int = <0x72038>;
				front_capture_cam = <0x6c660>;
				front_capture_mif = <0xcaa30>;
				front_capture_i2c = <0x00>;
				front_video_int = <0x72038>;
				front_video_cam = <0x6c660>;
				front_video_mif = <0xcaa30>;
				front_video_i2c = <0x00>;
				front_video_capture_int = <0x72038>;
				front_video_capture_cam = <0x6c660>;
				front_video_capture_mif = <0xcaa30>;
				front_video_capture_i2c = <0x00>;
				front_vt1_int = <0x72038>;
				front_vt1_cam = <0x6c660>;
				front_vt1_mif = <0xcaa30>;
				front_vt1_i2c = <0x00>;
				front_vt2_int = <0x72038>;
				front_vt2_cam = <0x6c660>;
				front_vt2_mif = <0xcaa30>;
				front_vt2_i2c = <0x00>;
				rear_preview_int = <0x72038>;
				rear_preview_cam = <0x87410>;
				rear_preview_mif = <0xcaa30>;
				rear_preview_i2c = <0x00>;
				rear_capture_int = <0x72038>;
				rear_capture_cam = <0x87410>;
				rear_capture_mif = <0xcaa30>;
				rear_capture_i2c = <0x00>;
				rear_video_int = <0x72038>;
				rear_video_cam = <0x87410>;
				rear_video_mif = <0xcaa30>;
				rear_video_i2c = <0x00>;
				rear_video_capture_int = <0x72038>;
				rear_video_capture_cam = <0x87410>;
				rear_video_capture_mif = <0xcaa30>;
				rear_video_capture_i2c = <0x00>;
				preview_high_speed_fps_int = <0x72038>;
				preview_high_speed_fps_cam = <0x87410>;
				preview_high_speed_fps_mif = <0xcaa30>;
				preview_high_speed_fps_i2c = <0x00>;
				video_high_speed_60fps_int = <0x72038>;
				video_high_speed_60fps_cam = <0x87410>;
				video_high_speed_60fps_mif = <0xcaa30>;
				video_high_speed_60fps_i2c = <0x00>;
				video_high_speed_120fps_int = <0x72038>;
				video_high_speed_120fps_cam = <0x87410>;
				video_high_speed_120fps_mif = <0xcaa30>;
				video_high_speed_120fps_i2c = <0x00>;
				max_int = <0x72038>;
				max_cam = <0xa2990>;
				max_mif = <0xcaa30>;
				max_i2c = <0x00>;
			};
		};
	};

	fm@14840000 {
		compatible = "samsung,exynos7570-fm";
		reg = <0x00 0x14840000 0x2000 0x00 0x11c80000 0x1000 0x00 0x10580000 0x100 0x00 0x148d0000 0x500 0x00 0x10460000 0x3000 0x00 0x13730000 0x2000 0x00 0x14880000 0x100>;
		interrupts = <0x00 0xc3 0x00>;
		clocks = <0x11 0x2e7>;
		clock-names = "oscclk_fm_52m_div";
		samsung,syscon-phandle = <0x0f>;
		samsung,power-domain = <0x65>;
		status = "okay";
		elna_gpio = <0x66 0x02 0x01>;
		pinctrl-names = "default";
		pinctrl-0 = <0x67>;
		fm_iclk_aux = <0x00>;
		fm_tc_on = <0x00>;
	};

	exynos-powermode {
		compatible = "exynos,powermode";
		wakeup_mask = <0x400f91e1 0x00 0x00 0x00 0x00 0x00 0x00 0x00 0x400ffffe>;
		wakeup_mask2 = <0x00 0x00 0x00 0x00 0x00 0x00 0x00 0x00 0xffff00ff>;
		wakeup_mask3 = <0x00 0x00 0x00 0x00 0x00 0x00 0x00 0x00 0xffff00ff>;
		cpd_residency = <0xbb8>;
		sicd_residency = <0xbb8>;
		sicd_enabled = <0x00>;
		idle-ip = "136c0000.pwm", "10550000.adc", "10510000.hsi2c", "13950000.hsi2c", "13960000.hsi2c", "138a0000.hsi2c", "138b0000.hsi2c", "138c0000.hsi2c", "138f0000.hsi2c", "13870000.i2c", "13880000.i2c", "13890000.i2c", "13840000.i2c", "13830000.i2c", "138d0000.i2c", "138e0000.i2c", "13850000.i2c", "13860000.i2c", "13540000.dwmmc0", "13560000.dwmmc2", "13600000.usb", "100c0000.spi", "13900000.spi", "13910000.spi", "13920000.spi", "13930000.spi", "10500000.mailbox-cp", "10570000.mailbox-gnss", "14830000.decon_fb", "pd-g3d", "pd-isp", "pd-mfcmscl", "148f0000.lpass";

		idle_ip_mask {

			SYS_SICD {
				mode-index = <0x00>;
				ref-idle-ip = <0x00 0x01 0x02 0x03 0x04 0x05 0x06 0x07 0x08 0x09 0x0a 0x0b 0x0c 0x0d 0x0e 0x0f 0x10 0x11 0x12 0x13 0x14 0x15 0x16 0x17 0x18 0x19 0x1a 0x1b 0x1c 0x1d 0x1e 0x1f 0x20>;
			};
		};
	};

	fips-fmp {
		compatible = "samsung,exynos-fips-fmp";
	};

	memory@40000000 {
		device_type = "memory";
		reg = <0x00 0x40000000 0x3f500000>;
	};

	chosen {
		bootargs = "console=ttySAC2,115200 clk_ignore_unused androidboot.hardware=samsungexynos7570 androidboot.selinux=disabled firmware_class.path=/vendor/firmware ess_setup=0x46000000 bcm_setup=0xffffff80f8e00000 androidboot.debug_level=0x4948 reserve-fimc=0";
		linux,initrd-start = <0x42000000>;
		linux,initrd-end = <0x421fffff>;
	};

	fixed-rate-clocks {

		oscclk {
			compatible = "samsung,exynos7570-oscclk";
			clock-frequency = <0x18cba80>;
		};
	};

	firmware {

		android {
			compatible = "android,firmware";

			fstab {
				compatible = "android,fstab";

				system {
					compatible = "android,system";
					dev = "/dev/block/platform/13540000.dwmmc0/by-name/SYSTEM";
					type = "ext4";
					mnt_flags = "ro";
					fsmgr_flags = "wait";
				};

				vendor {
					compatible = "android,vendor";
					dev = "/dev/block/platform/13540000.dwmmc0/by-name/VENDOR";
					type = "ext4";
					mnt_flags = "ro";
					fsmgr_flags = "wait";
				};

				odm {
					compatible = "android,odm";
					dev = "/dev/block/platform/13540000.dwmmc0/by-name/ODM";
					type = "ext4";
					mnt_flags = "ro";
					fsmgr_flags = "wait";
				};
			};
		};
	};

	ion {
		compatible = "samsung,exynos5430-ion";
	};

	decon_board {
		gpio_blic_on = <0x68 0x04 0x01>;
		gpio_panel_enp = <0x22 0x00 0x01>;
		gpio_panel_enn = <0x22 0x01 0x01>;
		gpio_lcd_rst = <0x69 0x00 0x01>;
		gpio_lcd_3p0 = <0x6a 0x00 0x01>;
		linux,phandle = <0x57>;
		phandle = <0x57>;

		dsim_set_panel_power_enable {
			type = "gpio,high", "gpio_lcd_3p0", "regulator,enable", "vdd_ldo2", "delay,usleep", "5000 6000";
		};

		dsim_set_panel_power_disable {
			type = "gpio,low", "gpio_lcd_rst", "delay,usleep", "10000 11000", "regulator,disable", "vdd_ldo2", "gpio,low", "gpio_lcd_3p0";
		};

		dsim_reset_panel {
			type = "gpio,high", "gpio_lcd_rst", "delay,usleep", "5000 6000", "gpio,low", "gpio_lcd_rst", "delay,usleep", "5000 6000", "gpio,high", "gpio_lcd_rst", "delay,msleep", "30";
		};
	};

	td4101_qhd {
		mode = <0x00>;
		panel_name = "td4101";
		resolution = <0x21c 0x3c0>;
		dispif_resol = <0x21c 0x3c0>;
		size = <0x3e 0x6e>;
		ddi_type = <0x00>;
		timing,refresh = <0x3c>;
		timing,dsim_h-porch = <0x28 0xf0 0x04>;
		timing,dsim_v-porch = <0x0d 0xf4 0x02>;
		timing,decon_h-porch = <0x28 0x433 0x04>;
		timing,decon_v-porch = <0x0d 0xf4 0x02>;
		timing,dsi-hs-clk = <0x2d8>;
		timing,pms = <0x02 0x70 0x01>;
		timing,dsi-escape-clk = <0x10>;
		clklane_onoff = <0x01>;
	};

	hs_tune {
		status = "okay";
		tx_vref = <0x03 0x03>;
		tx_pre_emp = <0x00 0x00>;
		tx_pre_emp_puls = <0x00 0x00>;
		tx_res = <0x02 0x02>;
		tx_rise = <0x01 0x01>;
		tx_hsxv = <0x00 0x00>;
		tx_fsls = <0x03 0x03>;
		rx_sqrx = <0x05 0x05>;
		compdis = <0x03 0x03>;
		otg = <0x02 0x02>;
		enable_user_imp = <0x00 0x00>;
		is_phyclock = <0x01>;
		linux,phandle = <0x61>;
		phandle = <0x61>;
	};

	ss_tune {
		status = "disabled";
		tx_boost_level = <0x04 0x04>;
		tx_swing_level = <0x01 0x01>;
		tx_swing_full = <0x7f 0x7f>;
		tx_swing_low = <0x7f 0x7f>;
		tx_deemphasis_mode = <0x01 0x01>;
		tx_deemphasis_3p5db = <0x18 0x18>;
		tx_deemphasis_6db = <0x18 0x18>;
		enable_ssc = <0x01 0x01>;
		ssc_range = <0x00 0x01>;
		los_bias = <0x05 0x05>;
		los_mask_val = <0x104 0x104>;
		enable_fixed_rxeq_mode = <0x00 0x00>;
		fix_rxeq_value = <0x04 0x04>;
		set_crport_mpll_charge_pump = <0x00 0x00>;
		set_crport_level_en = <0x00 0x00>;
		linux,phandle = <0x62>;
		phandle = <0x62>;
	};

	usb_notifier {
		compatible = "samsung,usb-notifier";
		udc = <0x6b>;
	};

	tmuctrl_CPUCL0@10130000 {
		compatible = "samsung,exynos7570-tmu";
		reg = <0x00 0x10130000 0x200>;
		interrupts = <0x00 0x1b3 0x00>;
		default_ptat_cont = <0x01>;
	};

	tmuctrl_G3D@10130000 {
		compatible = "samsung,exynos7570-tmu";
		reg = <0x00 0x10130000 0x200>;
		interrupts = <0x00 0x1b3 0x00>;
		default_ptat_cont = <0x01>;
		gpu_idx_num = <0x05>;
		gpu_cooling_table = <0x00 0x00 0xcaa30 0x00 0x01 0xa2990 0x00 0x02 0x87028 0x00 0x03 0x65518 0x00 0x04 0xfffffffe>;
	};

	gpio_keys {
		compatible = "gpio-keys";
		pinctrl-names = "default";
		pinctrl-0 = <0x6c 0x6d>;
		#address-cells = <0x01>;
		#size-cells = <0x00>;
		gpio-key,wakeup_enable;

		button@1 {
			label = "gpio-keys: KEY_VOLUMEUP";
			interrupts = <0x07 0x00 0x00>;
			interrupt-parent = <0x3a>;
			linux,code = <0x73>;
			gpios = <0x3a 0x07 0x0f>;
		};

		button@2 {
			label = "gpio-keys: KEY_VOLUMEDOWN";
			interrupts = <0x03 0x00 0x00>;
			interrupt-parent = <0x22>;
			linux,code = <0x72>;
			gpios = <0x22 0x03 0x0f>;
		};
	};

	i2c@20 {
		compatible = "i2c-gpio";
		gpios = <0x6e 0x00 0x00 0x6e 0x01 0x00>;
		i2c-gpio,delay-us = <0x05>;
		pinctrl-names = "default", "on_i2c", "off_i2c";
		pinctrl-0 = <0x6f>;
		pinctrl-1 = <0x6f>;
		pinctrl-2 = <0x70>;
		#address-cells = <0x01>;
		#size-cells = <0x00>;

		touchkey@20 {
			pinctrl-names = "default", "on_irq", "off_irq";
			pinctrl-0 = <0x71>;
			pinctrl-1 = <0x71>;
			pinctrl-2 = <0x72>;
			compatible = "coreriver,tc3xx-grip";
			reg = <0x20>;
			interrupts = <0x03 0x00 0x00>;
			interrupt-parent = <0x3a>;
			coreriver,scl-gpio = <0x6e 0x01 0x00>;
			coreriver,sda-gpio = <0x6e 0x00 0x00>;
			coreriver,irq-gpio = <0x3a 0x02 0x00>;
			coreriver,i2c-gpio = "true";
			coreriver,boot-on-ldo = "true";
			coreriver,regulator_ic = "vtouch_2.2v";
			coreriver,fw_name = "coreriver/tc305k_j2core_grip.fw";
			coreriver,sensing_ch_num = <0x04>;
			coreriver,tsk_ic_num = <0x01>;
			coreriver,use_bitmap = <0x01>;
		};
	};

	muic {
		status = "okay";
		muic,support-list = "+OTG:GND", "-MHL:1K", "-VZW Accessory:28.7K", "-VZW Incompatible:34K", "-Smartdock:40.2K", "-HMT:49.9K", "-Audiodock:64.9K", "-USB LANHUB:80.07K", "-Charging Cable:102K", "-Universal Multimedia dock:121K", "+Jig USB Off:255K", "+Jig USB On:301K", "+Deskdock:365K", "+TYPE2 Charger:442K", "+Jig UART Off:523K", "+Jig UART On:619K", "+TA:OPEN", "+USB:OPEN", "+CDP:OPEN", "+Undefined Charging:XXX";
	};

	fimc-is_sensor_4h5yc@37 {
		compatible = "samsung,sensor-module-4h5yc";
		pinctrl-names = "pin0", "pin1", "pin2";
		pinctrl-0;
		pinctrl-1 = <0x73 0x74>;
		pinctrl-2 = <0x75 0x74>;
		position = <0x00>;
		id = <0x00>;
		mclk_ch = <0x00>;
		sensor_i2c_ch = <0x00>;
		sensor_i2c_addr = <0x6e>;
		gpio_reset = <0x6a 0x01 0x01>;
		gpio_cam_core_en = <0x22 0x07 0x01>;
		status = "okay";

		af {
			product_name = <0x0d>;
			i2c_addr = <0x0c>;
			i2c_ch = <0x01>;
		};

		flash {
			product_name = <0x0d>;
			flash_first_gpio = <0x02>;
			flash_second_gpio = <0x01>;
		};
	};

	fimc-is_sensor_5e3@10 {
		compatible = "samsung,sensor-module-5e3";
		pinctrl-names = "pin0", "pin1", "pin2";
		pinctrl-0;
		pinctrl-1 = <0x73>;
		pinctrl-2 = <0x75>;
		position = <0x01>;
		id = <0x01>;
		mclk_ch = <0x00>;
		sensor_i2c_ch = <0x00>;
		sensor_i2c_addr = <0x10>;
		gpio_reset = <0x6a 0x06 0x01>;
		gpio_cam_core_en = <0x22 0x07 0x01>;
		status = "okay";
	};

	exynos_rgt {
		compatible = "samsung,exynos-rgt";
	};

	but_zones {
		#list-but-cells = <0x03>;
		linux,phandle = <0x38>;
		phandle = <0x38>;
	};

	acpm@11C88000 {
		compatible = "samsung,exynos-acpm";
		#address-cells = <0x02>;
		#size-cells = <0x01>;
		reg = <0x00 0x11c88000 0x1000>;
		log_base = <0x2047700>;
		time_len = <0x20>;
		log_buff_size = <0x10>;
		log_buff_len = <0x17c>;
		debug_logging_level = <0x00>;
		logging_period = <0x1f4>;
		dump_base = <0x2046000>;
		dump_size = <0x3800>;

		plugins {

			framework {
				attach = <0x02>;
				id = <0x00>;
				acpm-ipc-channel = <0x76>;
			};
		};
	};

	acpm_ipc@11C00000 {
		compatible = "samsung,exynos-acpm-ipc";
		#address-cells = <0x02>;
		#size-cells = <0x01>;
		interrupts = <0x00 0x16 0x00>;
		reg = <0x00 0x11c00000 0x1000>;

		channels {
			polling = <0x01>;
			max_buff_size = <0x300>;

			framework@0x02047400 {
				channel_id = <0x00>;
				rx_buff = <0x2047400>;
				tx_buff = <0x2047480>;
				buff_size = <0x0c>;
				buff_len = <0x08>;
				direction_buff = <0x19c>;
				linux,phandle = <0x76>;
				phandle = <0x76>;
			};
		};
	};

	dummy-i2s {
		compatible = "samsung,dummy-i2s";
		status = "okay";
	};

	cp_dummy {
		compatible = "samsung,cp_dummy";
		status = "okay";
		linux,phandle = <0x78>;
		phandle = <0x78>;
	};

	fm_dummy {
		compatible = "samsung,fm_dummy";
		status = "okay";
		linux,phandle = <0x7a>;
		phandle = <0x7a>;
	};

	bt_dummy {
		compatible = "samsung,bt_dummy";
		status = "okay";
		linux,phandle = <0x79>;
		phandle = <0x79>;
	};

	dummy-codec {
		compatible = "samsung,dummy-codec";
		status = "okay";
		linux,phandle = <0x7d>;
		phandle = <0x7d>;
	};

	sound {
		compatible = "samsung,universal7570-cod9002x";
		samsung,audio-cpu = <0x77 0x77 0x78 0x79 0x7a 0x7b 0x78 0x7c 0x7c 0x7c 0x7c>;
		samsung,audio-codec = <0x3b 0x3b 0x3b 0x7d 0x3b 0x7d 0x7d 0x3b 0x3b 0x3b 0x3b>;
		samsung,auxdev = <0x7e>;
		mic-bias-mode = <0x01 0x00 0x02 0x00>;
		status = "okay";
	};

	sec_thermistor@0 {
		compatible = "samsung,sec-ap-thermistor";
		status = "okay";
		adc_array = <0x11d 0x128 0x132 0x13d 0x147 0x152 0x15e 0x169 0x175 0x180 0x18c 0x198 0x1a4 0x1b1 0x1bd 0x1c9 0x1da 0x1eb 0x1fc 0x20d 0x21d 0x233 0x248 0x25d 0x272 0x288 0x29c 0x2b2 0x2c7 0x2dc 0x2f1 0x308 0x31e 0x336 0x34c 0x364 0x382 0x3a0 0x3be 0x3dc 0x3fa 0x41b 0x43c 0x45d 0x47e 0x49f 0x4c1 0x4e3 0x506 0x528 0x54a 0x573 0x59b 0x5c4 0x5ec 0x615 0x643 0x671 0x6a0 0x6cf 0x6fd 0x727 0x752 0x77d 0x7a7 0x7d1 0x801 0x831 0x861 0x892 0x8c2 0x8f3 0x924 0x955 0x985 0x9b5 0x9e3 0xa10 0xa3e 0xa6b 0xa99 0xac3 0xaed 0xb16 0xb40 0xb6a 0xb95 0xbbf 0xbea 0xc14 0xc3f 0xc60 0xc81 0xca3 0xcc4 0xce5 0xd02 0xd20 0xd3d 0xd5b 0xd78 0xd8e 0xda4 0xdba 0xdd0 0xde6 0xdfe 0xe17 0xe2f 0xe48 0xe60>;
		temp_array = <0x384 0x37a 0x370 0x366 0x35c 0x352 0x348 0x33e 0x334 0x32a 0x320 0x316 0x30c 0x302 0x2f8 0x2ee 0x2e4 0x2da 0x2d0 0x2c6 0x2bc 0x2b2 0x2a8 0x29e 0x294 0x28a 0x280 0x276 0x26c 0x262 0x258 0x24e 0x244 0x23a 0x230 0x226 0x21c 0x212 0x208 0x1fe 0x1f4 0x1ea 0x1e0 0x1d6 0x1cc 0x1c2 0x1b8 0x1ae 0x1a4 0x19a 0x190 0x186 0x17c 0x172 0x168 0x15e 0x154 0x14a 0x140 0x136 0x12c 0x122 0x118 0x10e 0x104 0xfa 0xf0 0xe6 0xdc 0xd2 0xc8 0xbe 0xb4 0xaa 0xa0 0x96 0x8c 0x82 0x78 0x6e 0x64 0x5a 0x50 0x46 0x3c 0x32 0x28 0x1e 0x14 0x0a 0x00 0xfffffff6 0xffffffec 0xffffffe2 0xffffffd8 0xffffffce 0xffffffc4 0xffffffba 0xffffffb0 0xffffffa6 0xffffff9c 0xffffff92 0xffffff88 0xffffff7e 0xffffff74 0xffffff6a 0xffffff60 0xffffff56 0xffffff4c 0xffffff42 0xffffff38>;
		io-channels = <0x37 0x00>;
		io-channel-names = "adc-ap-temp";
		io-channel-ranges;
	};

	argos {
		compatible = "samsung,argos";
		#address-cells = <0x01>;

		boot_device@1 {
			net_boost,label = "IPC";
			net_boost,node = "rmnet0 rmnet1 rmnet2 rmnet3 rmnet4 rmnet5 rmnet6 rmnet7 umts_dm0";
			net_boost,table_size = <0x04>;
			net_boost,table = <0x01 0x00 0x00 0x00 0x00 0x00 0x01 0x14 0xca648 0x00 0x65900 0x186a0 0x00 0x01 0x32 0xfde80 0x00 0xc96a8 0x186a0 0x00 0x01 0x64 0x15d1f0 0x00 0xc96a8 0x186a0 0x00 0x01>;
		};

		boot_device@2 {
			net_boost,label = "USB";
			net_boost,node = "rndis0";
			net_boost,table_size = <0x01>;
			net_boost,table = <0x01 0x00 0x00 0x00 0x00 0x00 0x01>;
		};

		boot_device@3 {
			net_boost,label = "P2P";
			net_boost,node = "p2p-wlan0-0";
			net_boost,table_size = <0x03>;
			net_boost,table = <0x1e 0x137090 0x00 0x65518 0x00 0x00 0x00 0x32 0x1506d0 0x00 0x65518 0x00 0x00 0x00 0x5a 0x1506d0 0x00 0xa2990 0x00 0x01 0x01>;
		};

		boot_device@4 {
			net_boost,label = "WIFI";
			net_boost,node = "wlan0";
			net_boost,table_size = <0x03>;
			net_boost,table = <0x0a 0xfde80 0x00 0x65518 0x00 0x00 0x00 0x3c 0x1506d0 0x00 0xa2990 0x00 0x01 0x01 0x78 0x1506d0 0x00 0xa2990 0x00 0x01 0x01>;
		};
	};

	input_booster {
		status = "okay";
		compatible = "input_booster";
		#address-cells = <0x01>;
		#size-cells = <0x00>;

		booster_key@1 {
			input_booster,label = "KEY";
			input_booster,type = <0x00>;
			input_booster,levels = <0x01>;
			input_booster,cpu_freqs = <0x137090>;
			input_booster,hmp_boost = <0x00>;
			input_booster,kfc_freqs = <0x137090>;
			input_booster,mif_freqs = <0x00>;
			input_booster,int_freqs = <0x00>;
			input_booster,head_times = <0x1f4>;
			input_booster,tail_times = <0x1f4>;
			input_booster,phase_times = <0x00>;
		};

		booster_key@2 {
			input_booster,label = "TOUCHKEY";
			input_booster,type = <0x01>;
			input_booster,levels = <0x01>;
			input_booster,cpu_freqs = <0x137090>;
			input_booster,hmp_boost = <0x00>;
			input_booster,kfc_freqs = <0x137090>;
			input_booster,mif_freqs = <0x00>;
			input_booster,int_freqs = <0x00>;
			input_booster,head_times = <0x00>;
			input_booster,tail_times = <0x12c>;
			input_booster,phase_times = <0x00>;
		};

		booster_key@3 {
			input_booster,label = "TOUCH";
			input_booster,type = <0x02>;
			input_booster,levels = <0x01 0x02 0x03>;
			input_booster,cpu_freqs = <0x137090 0x137090 0xeadd0>;
			input_booster,hmp_boost = <0x00 0x00 0x00>;
			input_booster,kfc_freqs = <0x137090 0x137090 0xeadd0>;
			input_booster,mif_freqs = <0x00 0x00 0x00>;
			input_booster,int_freqs = <0x00 0x00 0x00>;
			input_booster,head_times = <0xc8 0xc8 0x00>;
			input_booster,tail_times = <0x00 0x00 0x12c>;
			input_booster,phase_times = <0x00 0x00 0x00>;
		};

		booster_key@4 {
			input_booster,label = "MULTITOUCH";
			input_booster,type = <0x03>;
			input_booster,levels = <0x01 0x02>;
			input_booster,cpu_freqs = <0x1506d0 0xfde80>;
			input_booster,hmp_boost = <0x00 0x00>;
			input_booster,kfc_freqs = <0x1506d0 0xfde80>;
			input_booster,mif_freqs = <0x00 0x00>;
			input_booster,int_freqs = <0x00 0x00>;
			input_booster,head_times = <0x3e8 0x00>;
			input_booster,tail_times = <0x00 0x1f4>;
			input_booster,phase_times = <0x00 0x00>;
		};

		booster_key@5 {
			input_booster,label = "KEYBOARD";
			input_booster,type = <0x04>;
			input_booster,levels = <0x01 0x02>;
			input_booster,cpu_freqs = <0x137090 0x137090>;
			input_booster,hmp_boost = <0x00 0x00>;
			input_booster,kfc_freqs = <0x137090 0x137090>;
			input_booster,mif_freqs = <0x00 0x00>;
			input_booster,int_freqs = <0x00 0x00>;
			input_booster,head_times = <0xc8 0xc8>;
			input_booster,tail_times = <0x00 0x00>;
			input_booster,phase_times = <0x00 0x00>;
		};

		booster_key@6 {
			input_booster,label = "MOUSE";
			input_booster,type = <0x05>;
			input_booster,levels = <0x01 0x02>;
			input_booster,cpu_freqs = <0x137090 0xeadd0>;
			input_booster,hmp_boost = <0x00 0x00>;
			input_booster,kfc_freqs = <0x137090 0xeadd0>;
			input_booster,mif_freqs = <0x00 0x00>;
			input_booster,int_freqs = <0x00 0x00>;
			input_booster,head_times = <0xc8 0x00>;
			input_booster,tail_times = <0x00 0x12c>;
			input_booster,phase_times = <0x00 0x00>;
		};

		booster_key@7 {
			input_booster,label = "MOUSE WHEEL";
			input_booster,type = <0x06>;
			input_booster,levels = <0x01 0x02>;
			input_booster,cpu_freqs = <0x137090 0x00>;
			input_booster,hmp_boost = <0x00 0x00>;
			input_booster,kfc_freqs = <0x137090 0x00>;
			input_booster,mif_freqs = <0x00 0x00>;
			input_booster,int_freqs = <0x00 0x00>;
			input_booster,head_times = <0xc8 0x00>;
			input_booster,tail_times = <0x00 0x00>;
			input_booster,phase_times = <0x00 0x00>;
		};

		booster_key@8 {
			input_booster,label = "PEN & HOVER";
			input_booster,type = <0x07>;
			input_booster,levels = <0x01 0x02>;
			input_booster,cpu_freqs = <0x137090 0xeadd0>;
			input_booster,hmp_boost = <0x00 0x00>;
			input_booster,kfc_freqs = <0x137090 0xeadd0>;
			input_booster,mif_freqs = <0x00 0x00>;
			input_booster,int_freqs = <0x00 0x00>;
			input_booster,head_times = <0xc8 0x00>;
			input_booster,tail_times = <0x00 0x12c>;
			input_booster,phase_times = <0x00 0x00>;
		};

		booster_key@9 {
			input_booster,label = "GAMEPAD";
			input_booster,type = <0x08>;
			input_booster,levels = <0x01 0x02>;
			input_booster,cpu_freqs = <0x1506d0 0xca648>;
			input_booster,hmp_boost = <0x00 0x00>;
			input_booster,kfc_freqs = <0x1506d0 0xca648>;
			input_booster,mif_freqs = <0x00 0x00>;
			input_booster,int_freqs = <0x00 0x00>;
			input_booster,head_times = <0xc8 0x00>;
			input_booster,tail_times = <0x00 0x12c>;
			input_booster,phase_times = <0x00 0x00>;
		};
	};

	mif_pdata {
		compatible = "sec_modem,modem_pdata";
		status = "okay";
		interrupts = <0x00 0x12 0x00 0x00 0x1df 0x00>;
		mif,name = "ss305ap";
		mif,modem_net = <0x00>;
		mif,modem_type = <0x0a>;
		mif,use_handover = <0x00>;
		mif,ipc_version = <0x32>;
		mif,link_types = <0x200>;
		mif,link_name = "shmem";
		mif,link_attrs = <0x7c8>;
		mif,num_iodevs = <0x13>;
		mbx_ap2cp_msg = <0x00>;
		mbx_cp2ap_msg = <0x01>;
		mbx_ap2cp_united_status = <0x02>;
		mbx_cp2ap_united_status = <0x03>;
		mif,int_ap2cp_msg = <0x00>;
		mif,int_ap2cp_status = <0x02>;
		mif,int_ap2cp_active = <0x03>;
		mif,irq_cp2ap_msg = <0x00>;
		mif,irq_cp2ap_status = <0x02>;
		mif,irq_cp2ap_active = <0x03>;
		mif,irq_cp2ap_wake_lock = <0x08>;
		mbx_cp2ap_dvfsreq = <0x04>;
		mbx_cp2ap_dvfsreq_mif = <0x06>;
		mif,irq_cp2ap_perf_req_mif = <0x06>;
		mbx_ap2cp_cp_voltage_700 = <0x05>;
		mbx_ap2cp_cp_voltage_830 = <0x07>;
		sbi_evs_mode_mask = <0x01>;
		sbi_evs_mode_pos = <0x07>;
		sbi_lte_active_mask = <0x01>;
		sbi_lte_active_pos = <0x05>;
		sbi_cp_status_mask = <0x0f>;
		sbi_cp_status_pos = <0x01>;
		sbi_pda_active_mask = <0x01>;
		sbi_pda_active_pos = <0x05>;
		sbi_ap_status_mask = <0x0f>;
		sbi_ap_status_pos = <0x01>;
		sbi_ds_det_mask = <0x03>;
		sbi_ds_det_pos = <0x0e>;
		sbi_sys_rev_mask = <0xff>;
		sbi_sys_rev_pos = <0x06>;
		sbi_cp_cpu_freq_asv_mask = <0x07>;
		sbi_cp_cpu_freq_asv_pos = <0x13>;
		reg = <0x00 0x10000 0x00>;
		pinctrl-names = "default";
		pinctrl-0 = <0x7f>;

		iodevs {

			io_device_0 {
				iod,name = "umts_ipc0";
				iod,id = <0xeb>;
				iod,format = <0x00>;
				iod,io_type = <0x00>;
				iod,links = <0x200>;
				iod,attrs = <0x02>;
				iod,app = "RIL";
			};

			io_device_1 {
				iod,name = "umts_ipc1";
				iod,id = <0xec>;
				iod,format = <0x00>;
				iod,io_type = <0x00>;
				iod,links = <0x200>;
				iod,attrs = <0x02>;
				iod,app = "RIL";
			};

			io_device_2 {
				iod,name = "umts_rfs0";
				iod,id = <0xf5>;
				iod,format = <0x02>;
				iod,io_type = <0x00>;
				iod,links = <0x200>;
				iod,attrs = <0x02>;
				iod,app = "RFS";
			};

			io_device_3 {
				iod,name = "umts_csd";
				iod,id = <0x01>;
				iod,format = <0x01>;
				iod,io_type = <0x00>;
				iod,links = <0x200>;
				iod,attrs = <0x02>;
				iod,app = "CSVT";
			};

			io_device_4 {
				iod,name = "umts_router";
				iod,id = <0x19>;
				iod,format = <0x01>;
				iod,io_type = <0x00>;
				iod,links = <0x200>;
				iod,attrs = <0x02>;
				iod,app = "Data Router";
				iod,max_tx_size = <0x800>;
			};

			io_device_5 {
				iod,name = "umts_dm0";
				iod,id = <0x1c>;
				iod,format = <0x01>;
				iod,io_type = <0x00>;
				iod,links = <0x200>;
				iod,attrs = <0x02>;
				iod,app = "DIAG";
			};

			io_device_6 {
				iod,name = "rmnet0";
				iod,id = <0x0a>;
				iod,format = <0x01>;
				iod,io_type = <0x01>;
				iod,links = <0x200>;
				iod,attrs = <0x02>;
				iod,app = "NET";
			};

			io_device_7 {
				iod,name = "rmnet1";
				iod,id = <0x0b>;
				iod,format = <0x01>;
				iod,io_type = <0x01>;
				iod,links = <0x200>;
				iod,attrs = <0x02>;
				iod,app = "NET";
			};

			io_device_8 {
				iod,name = "rmnet2";
				iod,id = <0x0c>;
				iod,format = <0x01>;
				iod,io_type = <0x01>;
				iod,links = <0x200>;
				iod,attrs = <0x02>;
				iod,app = "NET";
			};

			io_device_9 {
				iod,name = "rmnet3";
				iod,id = <0x0d>;
				iod,format = <0x01>;
				iod,io_type = <0x01>;
				iod,links = <0x200>;
				iod,attrs = <0x02>;
				iod,app = "NET";
			};

			io_device_10 {
				iod,name = "rmnet4";
				iod,id = <0x0e>;
				iod,format = <0x01>;
				iod,io_type = <0x01>;
				iod,links = <0x200>;
				iod,attrs = <0x02>;
			};

			io_device_11 {
				iod,name = "rmnet5";
				iod,id = <0x0f>;
				iod,format = <0x01>;
				iod,io_type = <0x01>;
				iod,links = <0x200>;
				iod,attrs = <0x02>;
			};

			io_device_12 {
				iod,name = "rmnet6";
				iod,id = <0x10>;
				iod,format = <0x01>;
				iod,io_type = <0x01>;
				iod,links = <0x200>;
				iod,attrs = <0x02>;
			};

			io_device_13 {
				iod,name = "rmnet7";
				iod,id = <0x11>;
				iod,format = <0x01>;
				iod,io_type = <0x01>;
				iod,links = <0x200>;
				iod,attrs = <0x02>;
			};

			io_device_14 {
				iod,name = "multipdp";
				iod,id = <0x00>;
				iod,format = <0x03>;
				iod,io_type = <0x02>;
				iod,links = <0x200>;
				iod,attrs = <0x02>;
				iod,app = "RIL";
			};

			io_device_15 {
				iod,name = "umts_boot0";
				iod,id = <0xd7>;
				iod,format = <0x04>;
				iod,io_type = <0x00>;
				iod,links = <0x200>;
				iod,attrs = <0x02>;
				iod,app = "CBD";
			};

			io_device_16 {
				iod,name = "umts_ramdump0";
				iod,id = <0xe1>;
				iod,format = <0x05>;
				iod,io_type = <0x00>;
				iod,links = <0x200>;
				iod,attrs = <0x202>;
				iod,app = "CBD";
			};

			io_device_17 {
				iod,name = "smd4";
				iod,id = <0x21>;
				iod,format = <0x01>;
				iod,io_type = <0x00>;
				iod,links = <0x200>;
				iod,attrs = <0x802>;
				iod,option_region = "kor_skt";
			};

			io_device_18 {
				iod,name = "umts_ciq0";
				iod,id = <0x1a>;
				iod,format = <0x01>;
				iod,io_type = <0x00>;
				iod,links = <0x200>;
				iod,attrs = <0x802>;
				iod,option_region = "usa_att";
			};
		};
	};

	shmem@90000000 {
		compatible = "samsung,exynos-shm_ipc";
		shmem,ipc_offset = <0x4b00000>;
		shmem,ipc_size = <0x100000>;
	};

	s2mpu06-fuelgauge {
		status = "disable";
		compatible = "samsung,s2mpu06-fuelgauge";
		fuelgauge,fuel_alert_soc = <0x01>;
		fuelgauge,capacity_max = <0x3e8>;
		fuelgauge,capacity_max_margin = <0x96>;
		fuelgauge,capacity_min = <0x00>;
		fuelgauge,capacity_calculation_type = <0x1c>;
		fuelgauge,type_str = "SDI";
		fuelgauge,model_type = <0x01>;
		fuelgauge,cell_character = <0x70 0x0a 0xf9 0x09 0x83 0x09 0x19 0x09 0xb3 0x08 0x5a 0x08 0xe6 0x07 0xae 0x07 0x67 0x07 0xfe 0x06 0xbb 0x06 0x8f 0x06 0x6c 0x06 0x52 0x06 0x3d 0x06 0x29 0x06 0x01 0x06 0xd6 0x05 0x95 0x05 0x81 0x05 0x59 0x04 0x2b 0x03 0x6a 0x08 0x00 0x08 0x95 0x07 0x2b 0x07 0xc0 0x06 0x56 0x06 0xeb 0x05 0x81 0x05 0x16 0x05 0xac 0x04 0x41 0x04 0xd7 0x03 0x6c 0x03 0x02 0x03 0x97 0x02 0x2d 0x02 0xc2 0x01 0x58 0x01 0xed 0x00 0x83 0x00 0x18 0x00 0xf5 0x0f 0xfe 0x29 0xdc 0x29 0x8a 0x29 0x4d 0x29 0x28 0x1f 0x23 0x10 0x21 0x21 0x14 0x21 0xe9 0xf7 0xe6 0xf7 0xd3 0xde 0xca 0xd4 0xd3 0xd4 0x40 0x80 0x26 0x33 0x26 0x40 0x26 0x5c 0x26 0x5c 0x26 0x5c 0xff 0xff 0x02 0x05 0x14 0x0b 0x03 0x12 0x06 0x1c 0x0c 0x1c 0x10 0x1c 0x1f 0x1f 0x40 0x40 0x40 0x40 0x40 0x40 0x41 0x41 0x40 0x40 0x40 0x41 0x42 0x43 0x44 0x46 0x47 0x4b 0x51 0x62 0x88 0x80 0xec 0x28 0x0a 0x00 0x00 0x3e 0x0a 0xcf 0x09 0x60 0x09 0xfc 0x08 0xa3 0x08 0x3b 0x08 0xdf 0x07 0xa8 0x07 0x66 0x07 0x00 0x07 0xbe 0x06 0x93 0x06 0x71 0x06 0x56 0x06 0x40 0x06 0x33 0x06 0x11 0x06 0xed 0x05 0xb8 0x05 0x88 0x05 0x60 0x05 0x20 0x03 0x68 0x08 0x00 0x08 0x98 0x07 0x2f 0x07 0xc7 0x06 0x5f 0x06 0xf6 0x05 0x8e 0x05 0x26 0x05 0xbd 0x04 0x55 0x04 0xed 0x03 0x84 0x03 0x1c 0x03 0xb4 0x02 0x4b 0x02 0xe3 0x01 0x7a 0x01 0x12 0x01 0xaa 0x00 0x42 0x00 0xdf 0x0f 0xfe 0x29 0xdc 0x29 0x8a 0x29 0x4d 0x29 0x28 0x1f 0x23 0x10 0x21 0x21 0x14 0x21 0xe9 0xf7 0xe6 0xf7 0xd3 0xde 0xca 0xd4 0xd3 0xd4 0x40 0x80 0x26 0x33 0x26 0x40 0x26 0x5c 0x26 0x5c 0x26 0x5c 0xff 0xff 0x02 0x05 0x14 0x0b 0x03 0x12 0x06 0x1c 0x0c 0x1c 0x10 0x1c 0x1f 0x1f 0x44 0x44 0x45 0x45 0x45 0x44 0x46 0x46 0x45 0x46 0x46 0x47 0x48 0x4a 0x4b 0x4d 0x4f 0x54 0x5d 0x6f 0x92 0xd6 0xec 0x33 0x09 0x00 0x00 0xab 0x09 0x42 0x09 0xe2 0x08 0x94 0x08 0x20 0x08 0xda 0x07 0xa1 0x07 0x60 0x07 0xfb 0x06 0xbe 0x06 0x94 0x06 0x73 0x06 0x59 0x06 0x43 0x06 0x35 0x06 0x17 0x06 0xf5 0x05 0xc6 0x05 0x8d 0x05 0x7f 0x05 0x49 0x04 0xc3 0x02 0x00 0x08 0x9b 0x07 0x35 0x07 0xd0 0x06 0x6b 0x06 0x05 0x06 0xa0 0x05 0x3b 0x05 0xd5 0x04 0x70 0x04 0x0a 0x04 0xa5 0x03 0x40 0x03 0xda 0x02 0x75 0x02 0x10 0x02 0xaa 0x01 0x45 0x01 0xdf 0x00 0x7a 0x00 0x15 0x00 0xec 0x0f 0xfe 0x29 0xdc 0x29 0x8a 0x29 0x4d 0x29 0x28 0x1f 0x23 0x10 0x21 0x21 0x14 0x21 0xe9 0xf7 0xe6 0xf7 0xd3 0xde 0xca 0xd4 0xd3 0xd4 0x40 0x80 0x26 0x33 0x26 0x40 0x26 0x5c 0x26 0x5c 0x26 0x5c 0xff 0xff 0x02 0x05 0x14 0x0b 0x03 0x12 0x06 0x1c 0x0c 0x1c 0x10 0x1c 0x1f 0x1f 0x43 0x43 0x43 0x44 0x44 0x45 0x44 0x44 0x45 0x45 0x46 0x47 0x49 0x4a 0x4c 0x4d 0x51 0x58 0x63 0x7d 0xaf 0xc0 0xec 0x1f 0x09 0x00 0x00>;
		fuelgauge,raw_100_vbat = <0x1097 0x1082 0x1071>;
	};

	battery {
		status = "okay";
		pinctrl-names = "default";
		compatible = "samsung,sec-battery";
		battery,vendor = "SDI SDI";
		battery,charger_name = "s2mpu06-charger";
		battery,fuelgauge_name = "s2mpu06-fuelgauge";
		battery,technology = <0x02>;
		battery,chip_vendor = "LSI";
		battery,temp_adc_type = <0x01>;
		battery,polling_time = <0x0a 0x1e 0x1e 0x1e 0xe10>;
		battery,temp_table_adc = <0x12c 0x162 0x19c 0x1ea 0x235 0x295 0x31b 0x38c 0x423 0x4ba 0x4f6 0x55c 0x622 0x6f4 0x7da 0x8c0 0x9bf 0xaa6 0xb6d 0xc36 0xcaa 0xcfc 0xd8d 0xe07 0xe69>;
		battery,temp_table_data = <0x384 0x352 0x320 0x2ee 0x2bc 0x28a 0x258 0x226 0x1f4 0x1c2 0x1ae 0x190 0x15e 0x12c 0xfa 0xc8 0x96 0x64 0x32 0x00 0xffffffe2 0xffffffce 0xffffff9c 0xffffff6a 0xffffff38>;
		battery,wireless_cc_cv = <0x56>;
		battery,inbat_voltage = <0x01>;
		battery,inbat_voltage_table_adc = <0xae5 0xadd 0xacc 0xabb 0xab1 0xa92 0xa8a 0xa76 0xa60 0xa43 0xa30 0xa29 0xa18 0xa05 0x9fc 0x9f1 0x9ec 0x9e0 0x9d2 0x9c9 0x9bb 0x9b3 0x9a8 0x995 0x985 0x973 0x95e 0x946 0x93d 0x92c 0x90f 0x8ee>;
		battery,inbat_voltage_table_data = <0x10fe 0x10ea 0x10cc 0x10ae 0x109a 0x1068 0x1054 0x102c 0x1004 0xfd2 0xfaa 0xfa0 0xf8c 0xf6e 0xf5a 0xf46 0xf3c 0xf28 0xf14 0xf00 0xee2 0xed8 0xec4 0xea6 0xe88 0xe60 0xe38 0xe10 0xdfc 0xdde 0xdac 0xd7a>;
		battery,adc_check_count = <0x05>;
		battery,cable_check_type = <0x04>;
		battery,cable_source_type = <0x01>;
		battery,polling_type = <0x01>;
		battery,monitor_initial_count = <0x00>;
		battery,battery_check_type = <0x05>;
		battery,check_count = <0x00>;
		battery,ovp_uvlo_check_type = <0x03>;
		battery,check_adc_max = <0x5a0>;
		battery,check_adc_min = <0x00>;
		battery,thermal_source = <0x02>;
		battery,temp_check_type = <0x02>;
		battery,temp_check_count = <0x01>;
		battery,temp_highlimit_threshold_normal = <0x320>;
		battery,temp_highlimit_recovery_normal = <0x2ee>;
		battery,temp_high_threshold_normal = <0x1f4>;
		battery,temp_high_recovery_normal = <0x1c2>;
		battery,temp_low_threshold_normal = <0x00>;
		battery,temp_low_recovery_normal = <0x32>;
		battery,temp_highlimit_threshold_lpm = <0x320>;
		battery,temp_highlimit_recovery_lpm = <0x2ee>;
		battery,temp_high_threshold_lpm = <0x1f4>;
		battery,temp_high_recovery_lpm = <0x1c2>;
		battery,temp_low_threshold_lpm = <0x00>;
		battery,temp_low_recovery_lpm = <0x32>;
		battery,full_check_type = <0x07>;
		battery,full_check_type_2nd = <0x07>;
		battery,full_check_count = <0x01>;
		battery,chg_gpio_full_check = <0x00>;
		battery,chg_polarity_full_check = <0x01>;
		battery,chg_high_temp_1st = <0x212>;
		battery,chg_high_temp_2nd = <0x212>;
		battery,chg_high_temp_recovery = <0x20d>;
		battery,chg_charging_limit_current = <0x514>;
		battery,chg_charging_limit_current_2nd = <0x514>;
		battery,chg_skip_check_capacity = <0x0a>;
		battery,chg_skip_check_time = <0x258>;
		battery,wpc_high_temp = <0x1a4>;
		battery,wpc_high_temp_recovery = <0x19a>;
		battery,wpc_charging_limit_current = <0x1c2>;
		battery,full_condition_type = <0x0f>;
		battery,full_condition_soc = <0x5d>;
		battery,full_condition_vcell = <0x1068>;
		battery,recharge_check_count = <0x02>;
		battery,recharge_condition_type = <0x04>;
		battery,recharge_condition_soc = <0x62>;
		battery,recharge_condition_vcell = <0x1068>;
		battery,standard_curr = <0x415>;
		battery,recharging_expired_time = <0x1518>;
		battery,expired_time = <0x41a0>;
		battery,chg_float_voltage = <0x10cc>;
		battery,age_data = <0x00 0x10cc 0x1068 0x1068 0x5d 0x1c 0x10b8 0x1054 0x1054 0x5b 0x24 0x10a4 0x1040 0x1040 0x59>;
		battery,swelling_high_temp_block = <0x19a>;
		battery,swelling_high_temp_recov = <0x186>;
		battery,swelling_low_temp_2step_mode = <0x01>;
		battery,swelling_low_temp_block_1st = <0x96>;
		battery,swelling_low_temp_recov_1st = <0xc8>;
		battery,swelling_low_temp_block_2nd = <0x32>;
		battery,swelling_low_temp_recov_2nd = <0x64>;
		battery,swelling_low_temp_current = <0x2e4>;
		battery,swelling_low_temp_topoff = <0x82>;
		battery,swelling_high_temp_current = <0x460>;
		battery,swelling_high_temp_topoff = <0x82>;
		battery,swelling_drop_float_voltage = <0x1004>;
		battery,swelling_high_rechg_voltage = <0xf6e>;
		battery,swelling_low_rechg_voltage = <0xf6e>;
		battery,charging_by_single;
		battery,call_event_siop_level = <0x64>;
		battery,call_event_input = <0x4b0>;
		battery,call_event_output = <0x2d0>;
		io-channels = <0x37 0x01 0x37 0x05>;
		io-channel-names = "adc-temp", "adc-in-bat";
		#io-channel-cells = <0x02>;
		io-channel-ranges;
	};

	s2mpu06-charger {
		status = "disable";
		compatible = "samsung,s2mpu06-charger";
		battery,is_1MHz_switching = <0x01>;
		battery,chg_gpio_en = <0x00>;
		battery,chg_polarity_en = <0x00>;
		battery,chg_gpio_status = <0x00>;
		battery,chg_polarity_status = <0x00>;
	};

	cable-info {
		default_input_current = <0x3e8>;
		default_charging_current = <0x4b0>;
		full_check_current_1st = <0x104>;
		full_check_current_2nd = <0x82>;

		current_group_1 {
			cable_number = <0x01 0x04 0x13 0x15 0x16 0x17 0x1e>;
			input_current = <0x1f4>;
			charging_current = <0x1f4>;
		};

		current_group_2 {
			cable_number = <0x02 0x19>;
			input_current = <0x3e8>;
			charging_current = <0x3e8>;
		};

		current_group_3 {
			cable_number = <0x05>;
			input_current = <0x5dc>;
			charging_current = <0x5dc>;
		};

		current_group_4 {
			cable_number = <0x06 0x07 0x08>;
			input_current = <0x672>;
			charging_current = <0x866>;
		};

		current_group_5 {
			cable_number = <0x09>;
			input_current = <0x672>;
			charging_current = <0x866>;
		};

		current_group_6 {
			cable_number = <0x0a 0x0c 0x0e 0x0f 0x1b>;
			input_current = <0x384>;
			charging_current = <0x4b0>;
		};

		current_group_7 {
			cable_number = <0x0d>;
			input_current = <0x2bc>;
			charging_current = <0x4b0>;
		};

		current_group_8 {
			cable_number = <0x18>;
			input_current = <0x3e8>;
			charging_current = <0x1c2>;
		};

		current_group_9 {
			cable_number = <0x1a>;
			input_current = <0x7d0>;
			charging_current = <0x708>;
		};

		current_group_10 {
			cable_number = <0x0b 0x10 0x1c>;
			input_current = <0x28a>;
			charging_current = <0x4b0>;
		};

		current_group_11 {
			cable_number = <0x1d>;
			input_current = <0x1f4>;
			charging_current = <0x4b0>;
		};
	};

	exynos-pm {
		compatible = "samsung,exynos-pm";
		reg = <0x00 0x139f0000 0x1000 0x00 0x104e1200 0x100>;
		reg-names = "gpio_alive_base", "gicd_ispendrn_base";
		num-eint = <0x18>;
		num-gic = <0x10>;
		suspend_mode_idx = <0x08>;
		suspend_psci_idx = <0x83>;
		cp_call_mode_idx = <0x04>;
		cp_call_psci_idx = <0x84>;
	};

	sec_vib {
		compatible = "sec_vib";

		sec_vib_pdata {
			status = "okay";
			sec_vib,max_timeout = <0x2710>;
			sec_vib,ldo_type = <0x00>;
			sec_vib,regulator = "VDD_MOTOR_3P3";
		};
	};

	tsp_avdd {
		compatible = "regulator-fixed";
		regulator-name = "tsp_avdd";
		regulator-min-microvolt = <0x325aa0>;
		regulator-max-microvolt = <0x325aa0>;
		gpio = <0x66 0x03 0x00>;
		regulator-boot-on;
		enable-active-high;
	};

	fixedregulator@1 {
		compatible = "regulator-fixed";
		regulator-name = "vmmc";
		gpio = <0x3a 0x03 0x01>;
		regulator-min-microvolt = <0x2ab980>;
		regulator-max-microvolt = <0x2ab980>;
		regulator-initial-mode = <0x00>;
		enable-active-high;
		regulator-boot-on;
	};

	leds_ktd2692 {
		compatible = "ktd2692";
		flash_control = <0x25 0x03 0x01>;
		status = "okay";
		pinctrl-names = "default", "host", "is";
		pinctrl-0 = <0x80>;
		pinctrl-1 = <0x81>;
		pinctrl-2 = <0x80>;
	};

	s6d78a0_qhd {
		mode = <0x00>;
		resolution = <0x21c 0x3c0>;
		size = <0x44 0x79>;
		ddi_type = <0x00>;
		timing,refresh = <0x3c>;
		timing,dsim_h-porch = <0x23 0x23 0x1c>;
		timing,dsim_v-porch = <0x06 0x08 0x02>;
		timing,decon_h-porch = <0x23 0x2c2 0x1c>;
		timing,decon_v-porch = <0x06 0x08 0x02>;
		timing,dsi-hs-clk = <0x1cc>;
		timing,pms = <0x04 0x11b 0x02>;
		timing,dsi-escape-clk = <0x10>;
		backlight_info = <0x82>;
		linux,phandle = <0x56>;
		phandle = <0x56>;
	};

	ktd3102-bl {
		bl-ctrl = <0x68 0x04 0x01>;
		linux,phandle = <0x82>;
		phandle = <0x82>;
	};
};
